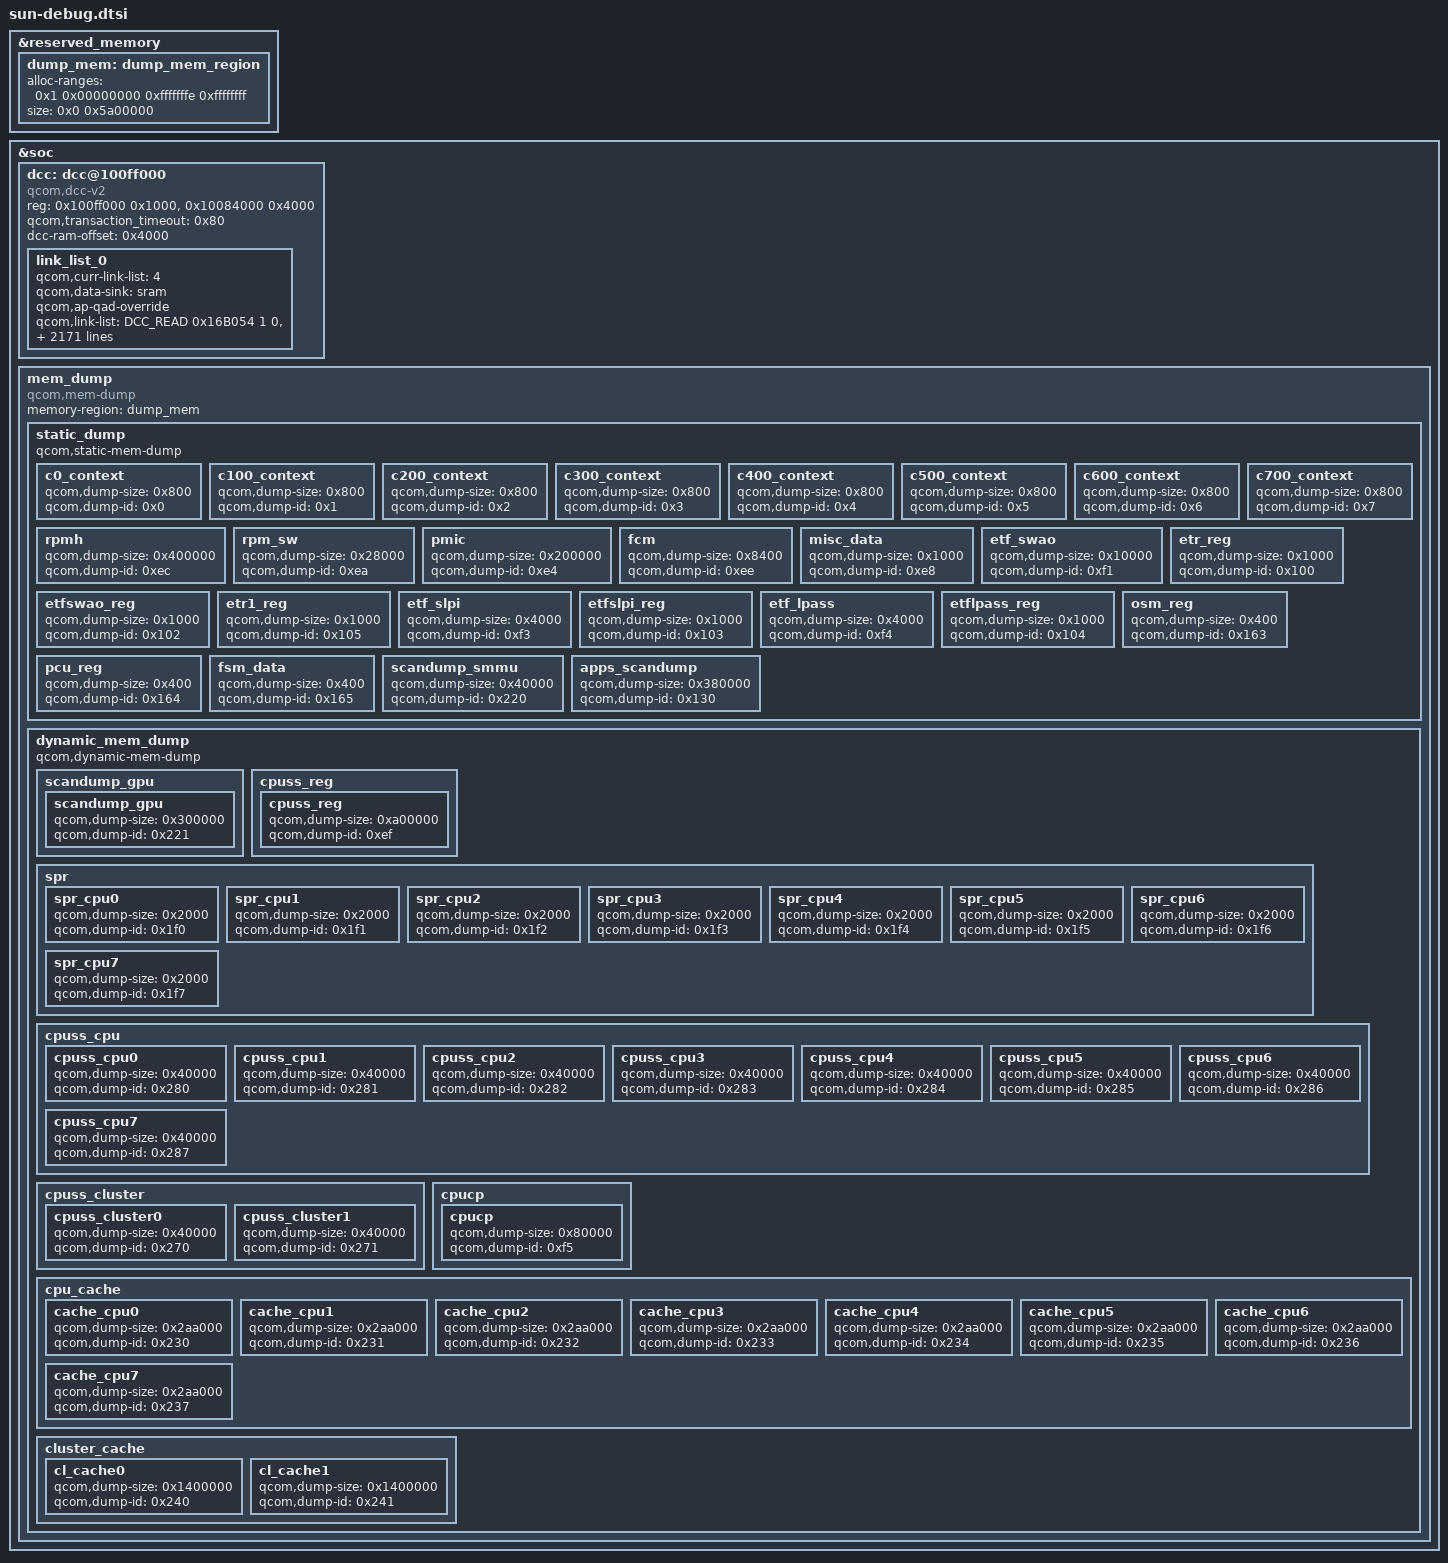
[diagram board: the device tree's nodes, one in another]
// SPDX-License-Identifier: BSD-3-Clause
/*
 * Copyright (c) 2023-2024 Qualcomm Innovation Center, Inc. All rights reserved.
 */

#include <dt-bindings/soc/qcom,dcc_v2.h>

&reserved_memory {
	#address-cells = <2>;
	#size-cells = <2>;
	ranges;

	dump_mem: dump_mem_region {
		alloc-ranges = <0x1 0x00000000 0xfffffffe 0xffffffff>;
		size = <0x0 0x5a00000>;
	};
};

&soc {
	dcc: dcc@100ff000 {
		compatible = "qcom,dcc-v2";
		reg = <0x100ff000 0x1000>,
		      <0x10084000 0x4000>;
		reg-names = "dcc-base", "dcc-ram-base";

		qcom,transaction_timeout = <0x80>;
		dcc-ram-offset = <0x4000>;

		link_list_0 {
			qcom,curr-link-list = <4>;
			qcom,data-sink = "sram";
			qcom,ap-qad-override;
			qcom,link-list = <DCC_READ 0x16B054  1 0>,
				<DCC_READ 0x16B080  1 0>,
				<DCC_READ 0x16B044  1 0>,
				<DCC_READ 0x16B040  1 0>,
				<DCC_READ 0x16B030  1 0>,
				<DCC_READ 0x16B020  1 0>,
				<DCC_READ 0x16B01C  1 0>,
				<DCC_READ 0x16B064  1 0>,
				<DCC_READ 0x11007C  1 0>,
				<DCC_READ 0x110068  1 0>,
				<DCC_READ 0x110058  1 0>,
				<DCC_READ 0xF204008 1 0>,
				<DCC_READ 0x1c06000 1 0>,
				<DCC_READ 0x1c06004 1 0>,
				<DCC_READ 0x1c06008 1 0>,
				<DCC_READ 0x1c0600c 1 0>,
				<DCC_READ 0x1c06010 1 0>,
				<DCC_READ 0x1c06014 1 0>,
				<DCC_READ 0x1c06018 1 0>,
				<DCC_READ 0x1c0601c 1 0>,
				<DCC_READ 0x1c06020 1 0>,
				<DCC_READ 0x1c06024 1 0>,
				<DCC_READ 0x1c06028 1 0>,
				<DCC_READ 0x1c0602c 1 0>,
				<DCC_READ 0x1c06030 1 0>,
				<DCC_READ 0x1c06034 1 0>,
				<DCC_READ 0x1c06038 1 0>,
				<DCC_READ 0x1c0603c 1 0>,
				<DCC_READ 0x1c06040 1 0>,
				<DCC_READ 0x1c06044 1 0>,
				<DCC_READ 0x1c06048 1 0>,
				<DCC_READ 0x1c0604c 1 0>,
				<DCC_READ 0x1c06050 1 0>,
				<DCC_READ 0x1c06054 1 0>,
				<DCC_READ 0x1c06058 1 0>,
				<DCC_READ 0x1c0605c 1 0>,
				<DCC_READ 0x1c06060 1 0>,
				<DCC_READ 0x1c06064 1 0>,
				<DCC_READ 0x1c06068 1 0>,
				<DCC_READ 0x1c0606c 1 0>,
				<DCC_READ 0x1c06070 1 0>,
				<DCC_READ 0x1c06074 1 0>,
				<DCC_READ 0x1c06078 1 0>,
				<DCC_READ 0x1c0607c 1 0>,
				<DCC_READ 0x1c06080 1 0>,
				<DCC_READ 0x1c06084 1 0>,
				<DCC_READ 0x1c06088 1 0>,
				<DCC_READ 0x1c0608c 1 0>,
				<DCC_READ 0x1c06090 1 0>,
				<DCC_READ 0x1c06094 1 0>,
				<DCC_READ 0x1c06098 1 0>,
				<DCC_READ 0x1c0609c 1 0>,
				<DCC_READ 0x1c060a0 1 0>,
				<DCC_READ 0x1c060a4 1 0>,
				<DCC_READ 0x1c060a8 1 0>,
				<DCC_READ 0x1c060ac 1 0>,
				<DCC_READ 0x1c060b0 1 0>,
				<DCC_READ 0x1c060b4 1 0>,
				<DCC_READ 0x1c060b8 1 0>,
				<DCC_READ 0x1c060bc 1 0>,
				<DCC_READ 0x1c060c0 1 0>,
				<DCC_READ 0x1c060c4 1 0>,
				<DCC_READ 0x1c060c8 1 0>,
				<DCC_READ 0x1c060cc 1 0>,
				<DCC_READ 0x1c060d0 1 0>,
				<DCC_READ 0x1c060d4 1 0>,
				<DCC_READ 0x1c060d8 1 0>,
				<DCC_READ 0x1c060dc 1 0>,
				<DCC_READ 0x1c060e0 1 0>,
				<DCC_READ 0x1c060e4 1 0>,
				<DCC_READ 0x1c060e8 1 0>,
				<DCC_READ 0x1c060ec 1 0>,
				<DCC_READ 0x1c060f0 1 0>,
				<DCC_READ 0x1c060f4 1 0>,
				<DCC_READ 0x1c060f8 1 0>,
				<DCC_READ 0x1c060fc 1 0>,
				<DCC_READ 0x1c06100 1 0>,
				<DCC_READ 0x1c06104 1 0>,
				<DCC_READ 0x1c06108 1 0>,
				<DCC_READ 0x1c0610c 1 0>,
				<DCC_READ 0x1c06110 1 0>,
				<DCC_READ 0x1c06114 1 0>,
				<DCC_READ 0x1c06118 1 0>,
				<DCC_READ 0x1c0611c 1 0>,
				<DCC_READ 0x1c06120 1 0>,
				<DCC_READ 0x1c06124 1 0>,
				<DCC_READ 0x1c06128 1 0>,
				<DCC_READ 0x1c0612c 1 0>,
				<DCC_READ 0x1c06130 1 0>,
				<DCC_READ 0x1c06134 1 0>,
				<DCC_READ 0x1c06138 1 0>,
				<DCC_READ 0x1c0613c 1 0>,
				<DCC_READ 0x1c06140 1 0>,
				<DCC_READ 0x1c06144 1 0>,
				<DCC_READ 0x1c06148 1 0>,
				<DCC_READ 0x1c0614c 1 0>,
				<DCC_READ 0x1c06150 1 0>,
				<DCC_READ 0x1c06154 1 0>,
				<DCC_READ 0x1c06158 1 0>,
				<DCC_READ 0x1c0615c 1 0>,
				<DCC_READ 0x1c06160 1 0>,
				<DCC_READ 0x1c06164 1 0>,
				<DCC_READ 0x1c06168 1 0>,
				<DCC_READ 0x1c0616c 1 0>,
				<DCC_READ 0x1c06170 1 0>,
				<DCC_READ 0x1c06174 1 0>,
				<DCC_READ 0x1c06178 1 0>,
				<DCC_READ 0x1c0617c 1 0>,
				<DCC_READ 0x1c06180 1 0>,
				<DCC_READ 0x1c06184 1 0>,
				<DCC_READ 0x1c06188 1 0>,
				<DCC_READ 0x1c0618c 1 0>,
				<DCC_READ 0x1c06190 1 0>,
				<DCC_READ 0x1c06194 1 0>,
				<DCC_READ 0x1c06198 1 0>,
				<DCC_READ 0x1c0619c 1 0>,
				<DCC_READ 0x1c061a0 1 0>,
				<DCC_READ 0x1c061a4 1 0>,
				<DCC_READ 0x1c061a8 1 0>,
				<DCC_READ 0x1c061ac 1 0>,
				<DCC_READ 0x1c061b0 1 0>,
				<DCC_READ 0x1c061b4 1 0>,
				<DCC_READ 0x1c061b8 1 0>,
				<DCC_READ 0x1c061bc 1 0>,
				<DCC_READ 0x1c061c0 1 0>,
				<DCC_READ 0x1c061c4 1 0>,
				<DCC_READ 0x1c061c8 1 0>,
				<DCC_READ 0x1c061cc 1 0>,
				<DCC_READ 0x1c061d0 1 0>,
				<DCC_READ 0x1c061d4 1 0>,
				<DCC_READ 0x1c061d8 1 0>,
				<DCC_READ 0x1c061dc 1 0>,
				<DCC_READ 0x1c061e0 1 0>,
				<DCC_READ 0x1c061e4 1 0>,
				<DCC_READ 0x1c061e8 1 0>,
				<DCC_READ 0x1c061ec 1 0>,
				<DCC_READ 0x1c061f0 1 0>,
				<DCC_READ 0x1c061f4 1 0>,
				<DCC_READ 0x1c061f8 1 0>,
				<DCC_READ 0x1c061fc 1 0>,
				<DCC_READ 0x1c06200 1 0>,
				<DCC_READ 0x1c06204 1 0>,
				<DCC_READ 0x1c06208 1 0>,
				<DCC_READ 0x1c0620c 1 0>,
				<DCC_READ 0x1c06210 1 0>,
				<DCC_READ 0x1c06214 1 0>,
				<DCC_READ 0x1c06218 1 0>,
				<DCC_READ 0x1c0621c 1 0>,
				<DCC_READ 0x1c06220 1 0>,
				<DCC_READ 0x1c06224 1 0>,
				<DCC_READ 0x1c06228 1 0>,
				<DCC_READ 0x1c0622c 1 0>,
				<DCC_READ 0x1c06230 1 0>,
				<DCC_READ 0x1c06234 1 0>,
				<DCC_READ 0x1c06238 1 0>,
				<DCC_READ 0x1c0623c 1 0>,
				<DCC_READ 0x1c06240 1 0>,
				<DCC_READ 0x1c06244 1 0>,
				<DCC_READ 0x1c06248 1 0>,
				<DCC_READ 0x1c0624c 1 0>,
				<DCC_READ 0x1c06250 1 0>,
				<DCC_READ 0x1c06254 1 0>,
				<DCC_READ 0x1c06258 1 0>,
				<DCC_READ 0x1c0625c 1 0>,
				<DCC_READ 0x1c06260 1 0>,
				<DCC_READ 0x1c06264 1 0>,
				<DCC_READ 0x1c06268 1 0>,
				<DCC_READ 0x1c0626c 1 0>,
				<DCC_READ 0x1c06270 1 0>,
				<DCC_READ 0x1c06274 1 0>,
				<DCC_READ 0x1c06278 1 0>,
				<DCC_READ 0x1c0627c 1 0>,
				<DCC_READ 0x1c06280 1 0>,
				<DCC_READ 0x1c06284 1 0>,
				<DCC_READ 0x1c06288 1 0>,
				<DCC_READ 0x1c0628c 1 0>,
				<DCC_READ 0x1c06290 1 0>,
				<DCC_READ 0x1c06294 1 0>,
				<DCC_READ 0x1c06298 1 0>,
				<DCC_READ 0x1c0629c 1 0>,
				<DCC_READ 0x1c062a0 1 0>,
				<DCC_READ 0x1c062a4 1 0>,
				<DCC_READ 0x1c062a8 1 0>,
				<DCC_READ 0x1c062ac 1 0>,
				<DCC_READ 0x1c062b0 1 0>,
				<DCC_READ 0x1c062b4 1 0>,
				<DCC_READ 0x1c062b8 1 0>,
				<DCC_READ 0x1c062bc 1 0>,
				<DCC_READ 0x1c062c0 1 0>,
				<DCC_READ 0x1c062c4 1 0>,
				<DCC_READ 0x1c062c8 1 0>,
				<DCC_READ 0x1c062cc 1 0>,
				<DCC_READ 0x1c062d0 1 0>,
				<DCC_READ 0x1c062d4 1 0>,
				<DCC_READ 0x1c062d8 1 0>,
				<DCC_READ 0x1c062dc 1 0>,
				<DCC_READ 0x1c062e0 1 0>,
				<DCC_READ 0x1c062e4 1 0>,
				<DCC_READ 0x1c062e8 1 0>,
				<DCC_READ 0x1c062ec 1 0>,
				<DCC_READ 0x1c062f0 1 0>,
				<DCC_READ 0x1c062f4 1 0>,
				<DCC_READ 0x1c062f8 1 0>,
				<DCC_READ 0x1c062fc 1 0>,
				<DCC_READ 0x1c06300 1 0>,
				<DCC_READ 0x1c06304 1 0>,
				<DCC_READ 0x1c06308 1 0>,
				<DCC_READ 0x1c0630c 1 0>,
				<DCC_READ 0x1c06310 1 0>,
				<DCC_READ 0x1c06314 1 0>,
				<DCC_READ 0x1c06318 1 0>,
				<DCC_READ 0x1c0631c 1 0>,
				<DCC_READ 0x1c06320 1 0>,
				<DCC_READ 0x1c06324 1 0>,
				<DCC_READ 0x1c06328 1 0>,
				<DCC_READ 0x1c0632c 1 0>,
				<DCC_READ 0x1c06330 1 0>,
				<DCC_READ 0x1c06334 1 0>,
				<DCC_READ 0x1c06338 1 0>,
				<DCC_READ 0x1c0633c 1 0>,
				<DCC_READ 0x1c06340 1 0>,
				<DCC_READ 0x1c06344 1 0>,
				<DCC_READ 0x1c06348 1 0>,
				<DCC_READ 0x1c0634c 1 0>,
				<DCC_READ 0x1c06350 1 0>,
				<DCC_READ 0x1c06354 1 0>,
				<DCC_READ 0x1c06358 1 0>,
				<DCC_READ 0x1c0635c 1 0>,
				<DCC_READ 0x1c06360 1 0>,
				<DCC_READ 0x1c06364 1 0>,
				<DCC_READ 0x1c06368 1 0>,
				<DCC_READ 0x1c0636c 1 0>,
				<DCC_READ 0x1c06370 1 0>,
				<DCC_READ 0x1c06374 1 0>,
				<DCC_READ 0x1c06378 1 0>,
				<DCC_READ 0x1c0637c 1 0>,
				<DCC_READ 0x1c06380 1 0>,
				<DCC_READ 0x1c06384 1 0>,
				<DCC_READ 0x1c06388 1 0>,
				<DCC_READ 0x1c0638c 1 0>,
				<DCC_READ 0x1c06390 1 0>,
				<DCC_READ 0x1c06394 1 0>,
				<DCC_READ 0x1c06398 1 0>,
				<DCC_READ 0x1c0639c 1 0>,
				<DCC_READ 0x1c063a0 1 0>,
				<DCC_READ 0x1c063a4 1 0>,
				<DCC_READ 0x1c063a8 1 0>,
				<DCC_READ 0x1c063ac 1 0>,
				<DCC_READ 0x1c063b0 1 0>,
				<DCC_READ 0x1c063b4 1 0>,
				<DCC_READ 0x1c063b8 1 0>,
				<DCC_READ 0x1c063bc 1 0>,
				<DCC_READ 0x1c063c0 1 0>,
				<DCC_READ 0x1c063c4 1 0>,
				<DCC_READ 0x1c063c8 1 0>,
				<DCC_READ 0x1c063cc 1 0>,
				<DCC_READ 0x1c063d0 1 0>,
				<DCC_READ 0x1c063d4 1 0>,
				<DCC_READ 0x1c063d8 1 0>,
				<DCC_READ 0x1c063dc 1 0>,
				<DCC_READ 0x1c063e0 1 0>,
				<DCC_READ 0x1c063e4 1 0>,
				<DCC_READ 0x1c063e8 1 0>,
				<DCC_READ 0x1c063ec 1 0>,
				<DCC_READ 0x1c063f0 1 0>,
				<DCC_READ 0x1c063f4 1 0>,
				<DCC_READ 0x1c063f8 1 0>,
				<DCC_READ 0x1c063fc 1 0>,
				<DCC_READ 0x1c06400 1 0>,
				<DCC_READ 0x1c06404 1 0>,
				<DCC_READ 0x1c06408 1 0>,
				<DCC_READ 0x1c0640c 1 0>,
				<DCC_READ 0x1c06410 1 0>,
				<DCC_READ 0x1c06414 1 0>,
				<DCC_READ 0x1c06418 1 0>,
				<DCC_READ 0x1c0641c 1 0>,
				<DCC_READ 0x1c06420 1 0>,
				<DCC_READ 0x1c06424 1 0>,
				<DCC_READ 0x1c06428 1 0>,
				<DCC_READ 0x1c0642c 1 0>,
				<DCC_READ 0x1c06430 1 0>,
				<DCC_READ 0x1c06434 1 0>,
				<DCC_READ 0x1c06438 1 0>,
				<DCC_READ 0x1c0643c 1 0>,
				<DCC_READ 0x1c06440 1 0>,
				<DCC_READ 0x1c06444 1 0>,
				<DCC_READ 0x1c06448 1 0>,
				<DCC_READ 0x1c0644c 1 0>,
				<DCC_READ 0x1c06450 1 0>,
				<DCC_READ 0x1c06454 1 0>,
				<DCC_READ 0x1c06458 1 0>,
				<DCC_READ 0x1c0645c 1 0>,
				<DCC_READ 0x1c06460 1 0>,
				<DCC_READ 0x1c06464 1 0>,
				<DCC_READ 0x1c06468 1 0>,
				<DCC_READ 0x1c0646c 1 0>,
				<DCC_READ 0x1c06470 1 0>,
				<DCC_READ 0x1c06474 1 0>,
				<DCC_READ 0x1c06478 1 0>,
				<DCC_READ 0x1c0647c 1 0>,
				<DCC_READ 0x1c06480 1 0>,
				<DCC_READ 0x1c06484 1 0>,
				<DCC_READ 0x1c06488 1 0>,
				<DCC_READ 0x1c0648c 1 0>,
				<DCC_READ 0x1c06490 1 0>,
				<DCC_READ 0x1c06494 1 0>,
				<DCC_READ 0x1c06498 1 0>,
				<DCC_READ 0x1c0649c 1 0>,
				<DCC_READ 0x1c064a0 1 0>,
				<DCC_READ 0x1c064a4 1 0>,
				<DCC_READ 0x1c064a8 1 0>,
				<DCC_READ 0x1c064ac 1 0>,
				<DCC_READ 0x1c064b0 1 0>,
				<DCC_READ 0x1c064b4 1 0>,
				<DCC_READ 0x1c064b8 1 0>,
				<DCC_READ 0x1c064bc 1 0>,
				<DCC_READ 0x1c064c0 1 0>,
				<DCC_READ 0x1c064c4 1 0>,
				<DCC_READ 0x1c064c8 1 0>,
				<DCC_READ 0x1c064cc 1 0>,
				<DCC_READ 0x1c064d0 1 0>,
				<DCC_READ 0x1c064d4 1 0>,
				<DCC_READ 0x1c064d8 1 0>,
				<DCC_READ 0x1c064dc 1 0>,
				<DCC_READ 0x1c064e0 1 0>,
				<DCC_READ 0x1c064e4 1 0>,
				<DCC_READ 0x1c064e8 1 0>,
				<DCC_READ 0x1c064ec 1 0>,
				<DCC_READ 0x1c064f0 1 0>,
				<DCC_READ 0x1c064f4 1 0>,
				<DCC_READ 0x1c064f8 1 0>,
				<DCC_READ 0x1c064fc 1 0>,
				<DCC_READ 0x1c06500 1 0>,
				<DCC_READ 0x1c06504 1 0>,
				<DCC_READ 0x1c06508 1 0>,
				<DCC_READ 0x1c0650c 1 0>,
				<DCC_READ 0x1c06510 1 0>,
				<DCC_READ 0x1c06514 1 0>,
				<DCC_READ 0x1c06518 1 0>,
				<DCC_READ 0x1c0651c 1 0>,
				<DCC_READ 0x1c06520 1 0>,
				<DCC_READ 0x1c06524 1 0>,
				<DCC_READ 0x1c06528 1 0>,
				<DCC_READ 0x1c0652c 1 0>,
				<DCC_READ 0x1c06530 1 0>,
				<DCC_READ 0x1c06534 1 0>,
				<DCC_READ 0x1c06538 1 0>,
				<DCC_READ 0x1c0653c 1 0>,
				<DCC_READ 0x1c06540 1 0>,
				<DCC_READ 0x1c06544 1 0>,
				<DCC_READ 0x1c06548 1 0>,
				<DCC_READ 0x1c0654c 1 0>,
				<DCC_READ 0x1c06550 1 0>,
				<DCC_READ 0x1c06554 1 0>,
				<DCC_READ 0x1c06558 1 0>,
				<DCC_READ 0x1c0655c 1 0>,
				<DCC_READ 0x1c06560 1 0>,
				<DCC_READ 0x1c06564 1 0>,
				<DCC_READ 0x1c06568 1 0>,
				<DCC_READ 0x1c0656c 1 0>,
				<DCC_READ 0x1c06570 1 0>,
				<DCC_READ 0x1c06574 1 0>,
				<DCC_READ 0x1c06578 1 0>,
				<DCC_READ 0x1c0657c 1 0>,
				<DCC_READ 0x1c06580 1 0>,
				<DCC_READ 0x1c06584 1 0>,
				<DCC_READ 0x1c06588 1 0>,
				<DCC_READ 0x1c0658c 1 0>,
				<DCC_READ 0x1c06590 1 0>,
				<DCC_READ 0x1c06594 1 0>,
				<DCC_READ 0x1c06598 1 0>,
				<DCC_READ 0x1c0659c 1 0>,
				<DCC_READ 0x1c065a0 1 0>,
				<DCC_READ 0x1c065a4 1 0>,
				<DCC_READ 0x1c065a8 1 0>,
				<DCC_READ 0x1c065ac 1 0>,
				<DCC_READ 0x1c065b0 1 0>,
				<DCC_READ 0x1c065b4 1 0>,
				<DCC_READ 0x1c065b8 1 0>,
				<DCC_READ 0x1c065bc 1 0>,
				<DCC_READ 0x1c065c0 1 0>,
				<DCC_READ 0x1c065c4 1 0>,
				<DCC_READ 0x1c065c8 1 0>,
				<DCC_READ 0x1c065cc 1 0>,
				<DCC_READ 0x1c065d0 1 0>,
				<DCC_READ 0x1c065d4 1 0>,
				<DCC_READ 0x1c065d8 1 0>,
				<DCC_READ 0x1c065dc 1 0>,
				<DCC_READ 0x1c065e0 1 0>,
				<DCC_READ 0x1c065e4 1 0>,
				<DCC_READ 0x1c065e8 1 0>,
				<DCC_READ 0x1c065ec 1 0>,
				<DCC_READ 0x1c065f0 1 0>,
				<DCC_READ 0x1c065f4 1 0>,
				<DCC_READ 0x1c065f8 1 0>,
				<DCC_READ 0x1c065fc 1 0>,
				<DCC_READ 0x1c06600 1 0>,
				<DCC_READ 0x1c06604 1 0>,
				<DCC_READ 0x1c06608 1 0>,
				<DCC_READ 0x1c0660c 1 0>,
				<DCC_READ 0x1c06610 1 0>,
				<DCC_READ 0x1c06614 1 0>,
				<DCC_READ 0x1c06618 1 0>,
				<DCC_READ 0x1c0661c 1 0>,
				<DCC_READ 0x1c06620 1 0>,
				<DCC_READ 0x1c06624 1 0>,
				<DCC_READ 0x1c06628 1 0>,
				<DCC_READ 0x1c0662c 1 0>,
				<DCC_READ 0x1c06630 1 0>,
				<DCC_READ 0x1c06634 1 0>,
				<DCC_READ 0x1c06638 1 0>,
				<DCC_READ 0x1c0663c 1 0>,
				<DCC_READ 0x1c06640 1 0>,
				<DCC_READ 0x1c06644 1 0>,
				<DCC_READ 0x1c06648 1 0>,
				<DCC_READ 0x1c0664c 1 0>,
				<DCC_READ 0x1c06650 1 0>,
				<DCC_READ 0x1c06654 1 0>,
				<DCC_READ 0x1c06658 1 0>,
				<DCC_READ 0x1c0665c 1 0>,
				<DCC_READ 0x1c06660 1 0>,
				<DCC_READ 0x1c06664 1 0>,
				<DCC_READ 0x1c06668 1 0>,
				<DCC_READ 0x1c0666c 1 0>,
				<DCC_READ 0x1c06670 1 0>,
				<DCC_READ 0x1c06674 1 0>,
				<DCC_READ 0x1c06678 1 0>,
				<DCC_READ 0x1c0667c 1 0>,
				<DCC_READ 0x1c06680 1 0>,
				<DCC_READ 0x1c06684 1 0>,
				<DCC_READ 0x1c06688 1 0>,
				<DCC_READ 0x1c0668c 1 0>,
				<DCC_READ 0x1c06690 1 0>,
				<DCC_READ 0x1c06694 1 0>,
				<DCC_READ 0x1c06698 1 0>,
				<DCC_READ 0x1c0669c 1 0>,
				<DCC_READ 0x1c066a0 1 0>,
				<DCC_READ 0x1c066a4 1 0>,
				<DCC_READ 0x1c066a8 1 0>,
				<DCC_READ 0x1c066ac 1 0>,
				<DCC_READ 0x1c066b0 1 0>,
				<DCC_READ 0x1c066b4 1 0>,
				<DCC_READ 0x1c066b8 1 0>,
				<DCC_READ 0x1c066bc 1 0>,
				<DCC_READ 0x1c066c0 1 0>,
				<DCC_READ 0x1c066c4 1 0>,
				<DCC_READ 0x1c066c8 1 0>,
				<DCC_READ 0x1c066cc 1 0>,
				<DCC_READ 0x1c066d0 1 0>,
				<DCC_READ 0x1c066d4 1 0>,
				<DCC_READ 0x1c066d8 1 0>,
				<DCC_READ 0x1c066dc 1 0>,
				<DCC_READ 0x1c066e0 1 0>,
				<DCC_READ 0x1c066e4 1 0>,
				<DCC_READ 0x1c066e8 1 0>,
				<DCC_READ 0x1c066ec 1 0>,
				<DCC_READ 0x1c066f0 1 0>,
				<DCC_READ 0x1c066f4 1 0>,
				<DCC_READ 0x1c066f8 1 0>,
				<DCC_READ 0x1c066fc 1 0>,
				<DCC_READ 0x1c06700 1 0>,
				<DCC_READ 0x1c06704 1 0>,
				<DCC_READ 0x1c06708 1 0>,
				<DCC_READ 0x1c0670c 1 0>,
				<DCC_READ 0x1c06710 1 0>,
				<DCC_READ 0x1c06714 1 0>,
				<DCC_READ 0x1c06718 1 0>,
				<DCC_READ 0x1c0671c 1 0>,
				<DCC_READ 0x1c06720 1 0>,
				<DCC_READ 0x1c06724 1 0>,
				<DCC_READ 0x1c06728 1 0>,
				<DCC_READ 0x1c0672c 1 0>,
				<DCC_READ 0x1c06730 1 0>,
				<DCC_READ 0x1c06734 1 0>,
				<DCC_READ 0x1c06738 1 0>,
				<DCC_READ 0x1c0673c 1 0>,
				<DCC_READ 0x1c06740 1 0>,
				<DCC_READ 0x1c06744 1 0>,
				<DCC_READ 0x1c06748 1 0>,
				<DCC_READ 0x1c0674c 1 0>,
				<DCC_READ 0x1c06750 1 0>,
				<DCC_READ 0x1c06754 1 0>,
				<DCC_READ 0x1c06758 1 0>,
				<DCC_READ 0x1c0675c 1 0>,
				<DCC_READ 0x1c06760 1 0>,
				<DCC_READ 0x1c06764 1 0>,
				<DCC_READ 0x1c06768 1 0>,
				<DCC_READ 0x1c0676c 1 0>,
				<DCC_READ 0x1c06770 1 0>,
				<DCC_READ 0x1c06774 1 0>,
				<DCC_READ 0x1c06778 1 0>,
				<DCC_READ 0x1c0677c 1 0>,
				<DCC_READ 0x1c06780 1 0>,
				<DCC_READ 0x1c06784 1 0>,
				<DCC_READ 0x1c06788 1 0>,
				<DCC_READ 0x1c0678c 1 0>,
				<DCC_READ 0x1c06790 1 0>,
				<DCC_READ 0x1c06794 1 0>,
				<DCC_READ 0x1c06798 1 0>,
				<DCC_READ 0x1c0679c 1 0>,
				<DCC_READ 0x1c067a0 1 0>,
				<DCC_READ 0x1c067a4 1 0>,
				<DCC_READ 0x1c067a8 1 0>,
				<DCC_READ 0x1c067ac 1 0>,
				<DCC_READ 0x1c067b0 1 0>,
				<DCC_READ 0x1c067b4 1 0>,
				<DCC_READ 0x1c067b8 1 0>,
				<DCC_READ 0x1c067bc 1 0>,
				<DCC_READ 0x1c067c0 1 0>,
				<DCC_READ 0x1c067c4 1 0>,
				<DCC_READ 0x1c067c8 1 0>,
				<DCC_READ 0x1c067cc 1 0>,
				<DCC_READ 0x1c067d0 1 0>,
				<DCC_READ 0x1c067d4 1 0>,
				<DCC_READ 0x1c067d8 1 0>,
				<DCC_READ 0x1c067dc 1 0>,
				<DCC_READ 0x1c067e0 1 0>,
				<DCC_READ 0x1c067e4 1 0>,
				<DCC_READ 0x1c067e8 1 0>,
				<DCC_READ 0x1c067ec 1 0>,
				<DCC_READ 0x1c067f0 1 0>,
				<DCC_READ 0x1c067f4 1 0>,
				<DCC_READ 0x1c067f8 1 0>,
				<DCC_READ 0x1c067fc 1 0>,
				<DCC_READ 0x1c06800 1 0>,
				<DCC_READ 0x1c06804 1 0>,
				<DCC_READ 0x1c06808 1 0>,
				<DCC_READ 0x1c0680c 1 0>,
				<DCC_READ 0x1c06810 1 0>,
				<DCC_READ 0x1c06814 1 0>,
				<DCC_READ 0x1c06818 1 0>,
				<DCC_READ 0x1c0681c 1 0>,
				<DCC_READ 0x1c06820 1 0>,
				<DCC_READ 0x1c06824 1 0>,
				<DCC_READ 0x1c06828 1 0>,
				<DCC_READ 0x1c0682c 1 0>,
				<DCC_READ 0x1c06830 1 0>,
				<DCC_READ 0x1c06834 1 0>,
				<DCC_READ 0x1c06838 1 0>,
				<DCC_READ 0x1c0683c 1 0>,
				<DCC_READ 0x1c06840 1 0>,
				<DCC_READ 0x1c06844 1 0>,
				<DCC_READ 0x1c06848 1 0>,
				<DCC_READ 0x1c0684c 1 0>,
				<DCC_READ 0x1c06850 1 0>,
				<DCC_READ 0x1c06854 1 0>,
				<DCC_READ 0x1c06858 1 0>,
				<DCC_READ 0x1c0685c 1 0>,
				<DCC_READ 0x1c06860 1 0>,
				<DCC_READ 0x1c06864 1 0>,
				<DCC_READ 0x1c06868 1 0>,
				<DCC_READ 0x1c0686c 1 0>,
				<DCC_READ 0x1c06870 1 0>,
				<DCC_READ 0x1c06874 1 0>,
				<DCC_READ 0x1c06878 1 0>,
				<DCC_READ 0x1c0687c 1 0>,
				<DCC_READ 0x1c06880 1 0>,
				<DCC_READ 0x1c06884 1 0>,
				<DCC_READ 0x1c06888 1 0>,
				<DCC_READ 0x1c0688c 1 0>,
				<DCC_READ 0x1c06890 1 0>,
				<DCC_READ 0x1c06894 1 0>,
				<DCC_READ 0x1c06898 1 0>,
				<DCC_READ 0x1c0689c 1 0>,
				<DCC_READ 0x1c068a0 1 0>,
				<DCC_READ 0x1c068a4 1 0>,
				<DCC_READ 0x1c068a8 1 0>,
				<DCC_READ 0x1c068ac 1 0>,
				<DCC_READ 0x1c068b0 1 0>,
				<DCC_READ 0x1c068b4 1 0>,
				<DCC_READ 0x1c068b8 1 0>,
				<DCC_READ 0x1c068bc 1 0>,
				<DCC_READ 0x1c068c0 1 0>,
				<DCC_READ 0x1c068c4 1 0>,
				<DCC_READ 0x1c068c8 1 0>,
				<DCC_READ 0x1c068cc 1 0>,
				<DCC_READ 0x1c068d0 1 0>,
				<DCC_READ 0x1c068d4 1 0>,
				<DCC_READ 0x1c068d8 1 0>,
				<DCC_READ 0x1c068dc 1 0>,
				<DCC_READ 0x1c068e0 1 0>,
				<DCC_READ 0x1c068e4 1 0>,
				<DCC_READ 0x1c068e8 1 0>,
				<DCC_READ 0x1c068ec 1 0>,
				<DCC_READ 0x1c068f0 1 0>,
				<DCC_READ 0x1c068f4 1 0>,
				<DCC_READ 0x1c068f8 1 0>,
				<DCC_READ 0x1c068fc 1 0>,
				<DCC_READ 0x1c06900 1 0>,
				<DCC_READ 0x1c06904 1 0>,
				<DCC_READ 0x1c06908 1 0>,
				<DCC_READ 0x1c0690c 1 0>,
				<DCC_READ 0x1c06910 1 0>,
				<DCC_READ 0x1c06914 1 0>,
				<DCC_READ 0x1c06918 1 0>,
				<DCC_READ 0x1c0691c 1 0>,
				<DCC_READ 0x1c06920 1 0>,
				<DCC_READ 0x1c06924 1 0>,
				<DCC_READ 0x1c06928 1 0>,
				<DCC_READ 0x1c0692c 1 0>,
				<DCC_READ 0x1c06930 1 0>,
				<DCC_READ 0x1c06934 1 0>,
				<DCC_READ 0x1c06938 1 0>,
				<DCC_READ 0x1c0693c 1 0>,
				<DCC_READ 0x1c06940 1 0>,
				<DCC_READ 0x1c06944 1 0>,
				<DCC_READ 0x1c06948 1 0>,
				<DCC_READ 0x1c0694c 1 0>,
				<DCC_READ 0x1c06950 1 0>,
				<DCC_READ 0x1c06954 1 0>,
				<DCC_READ 0x1c06958 1 0>,
				<DCC_READ 0x1c0695c 1 0>,
				<DCC_READ 0x1c06960 1 0>,
				<DCC_READ 0x1c06964 1 0>,
				<DCC_READ 0x1c06968 1 0>,
				<DCC_READ 0x1c0696c 1 0>,
				<DCC_READ 0x1c06970 1 0>,
				<DCC_READ 0x1c06974 1 0>,
				<DCC_READ 0x1c06978 1 0>,
				<DCC_READ 0x1c0697c 1 0>,
				<DCC_READ 0x1c06980 1 0>,
				<DCC_READ 0x1c06984 1 0>,
				<DCC_READ 0x1c06988 1 0>,
				<DCC_READ 0x1c0698c 1 0>,
				<DCC_READ 0x1c06990 1 0>,
				<DCC_READ 0x1c06994 1 0>,
				<DCC_READ 0x1c06998 1 0>,
				<DCC_READ 0x1c0699c 1 0>,
				<DCC_READ 0x1c069a0 1 0>,
				<DCC_READ 0x1c069a4 1 0>,
				<DCC_READ 0x1c069a8 1 0>,
				<DCC_READ 0x1c069ac 1 0>,
				<DCC_READ 0x1c069b0 1 0>,
				<DCC_READ 0x1c069b4 1 0>,
				<DCC_READ 0x1c069b8 1 0>,
				<DCC_READ 0x1c069bc 1 0>,
				<DCC_READ 0x1c069c0 1 0>,
				<DCC_READ 0x1c069c4 1 0>,
				<DCC_READ 0x1c069c8 1 0>,
				<DCC_READ 0x1c069cc 1 0>,
				<DCC_READ 0x1c069d0 1 0>,
				<DCC_READ 0x1c069d4 1 0>,
				<DCC_READ 0x1c069d8 1 0>,
				<DCC_READ 0x1c069dc 1 0>,
				<DCC_READ 0x1c069e0 1 0>,
				<DCC_READ 0x1c069e4 1 0>,
				<DCC_READ 0x1c069e8 1 0>,
				<DCC_READ 0x1c069ec 1 0>,
				<DCC_READ 0x1c069f0 1 0>,
				<DCC_READ 0x1c069f4 1 0>,
				<DCC_READ 0x1c069f8 1 0>,
				<DCC_READ 0x1c069fc 1 0>,
				<DCC_READ 0x1c06a00 1 0>,
				<DCC_READ 0x1c06a04 1 0>,
				<DCC_READ 0x1c06a08 1 0>,
				<DCC_READ 0x1c06a0c 1 0>,
				<DCC_READ 0x1c06a10 1 0>,
				<DCC_READ 0x1c06a14 1 0>,
				<DCC_READ 0x1c06a18 1 0>,
				<DCC_READ 0x1c06a1c 1 0>,
				<DCC_READ 0x1c06a20 1 0>,
				<DCC_READ 0x1c06a24 1 0>,
				<DCC_READ 0x1c06a28 1 0>,
				<DCC_READ 0x1c06a2c 1 0>,
				<DCC_READ 0x1c06a30 1 0>,
				<DCC_READ 0x1c06a34 1 0>,
				<DCC_READ 0x1c06a38 1 0>,
				<DCC_READ 0x1c06a3c 1 0>,
				<DCC_READ 0x1c06a40 1 0>,
				<DCC_READ 0x1c06a44 1 0>,
				<DCC_READ 0x1c06a48 1 0>,
				<DCC_READ 0x1c06a4c 1 0>,
				<DCC_READ 0x1c06a50 1 0>,
				<DCC_READ 0x1c06a54 1 0>,
				<DCC_READ 0x1c06a58 1 0>,
				<DCC_READ 0x1c06a5c 1 0>,
				<DCC_READ 0x1c06a60 1 0>,
				<DCC_READ 0x1c06a64 1 0>,
				<DCC_READ 0x1c06a68 1 0>,
				<DCC_READ 0x1c06a6c 1 0>,
				<DCC_READ 0x1c06a70 1 0>,
				<DCC_READ 0x1c06a74 1 0>,
				<DCC_READ 0x1c06a78 1 0>,
				<DCC_READ 0x1c06a7c 1 0>,
				<DCC_READ 0x1c06a80 1 0>,
				<DCC_READ 0x1c06a84 1 0>,
				<DCC_READ 0x1c06a88 1 0>,
				<DCC_READ 0x1c06a8c 1 0>,
				<DCC_READ 0x1c06a90 1 0>,
				<DCC_READ 0x1c06a94 1 0>,
				<DCC_READ 0x1c06a98 1 0>,
				<DCC_READ 0x1c06a9c 1 0>,
				<DCC_READ 0x1c06aa0 1 0>,
				<DCC_READ 0x1c06aa4 1 0>,
				<DCC_READ 0x1c06aa8 1 0>,
				<DCC_READ 0x1c06aac 1 0>,
				<DCC_READ 0x1c06ab0 1 0>,
				<DCC_READ 0x1c06ab4 1 0>,
				<DCC_READ 0x1c06ab8 1 0>,
				<DCC_READ 0x1c06abc 1 0>,
				<DCC_READ 0x1c06ac0 1 0>,
				<DCC_READ 0x1c06ac4 1 0>,
				<DCC_READ 0x1c06ac8 1 0>,
				<DCC_READ 0x1c06acc 1 0>,
				<DCC_READ 0x1c06ad0 1 0>,
				<DCC_READ 0x1c06ad4 1 0>,
				<DCC_READ 0x1c06ad8 1 0>,
				<DCC_READ 0x1c06adc 1 0>,
				<DCC_READ 0x1c06ae0 1 0>,
				<DCC_READ 0x1c06ae4 1 0>,
				<DCC_READ 0x1c06ae8 1 0>,
				<DCC_READ 0x1c06aec 1 0>,
				<DCC_READ 0x1c06af0 1 0>,
				<DCC_READ 0x1c06af4 1 0>,
				<DCC_READ 0x1c06af8 1 0>,
				<DCC_READ 0x1c06afc 1 0>,
				<DCC_READ 0x1c06b00 1 0>,
				<DCC_READ 0x1c06b04 1 0>,
				<DCC_READ 0x1c06b08 1 0>,
				<DCC_READ 0x1c06b0c 1 0>,
				<DCC_READ 0x1c06b10 1 0>,
				<DCC_READ 0x1c06b14 1 0>,
				<DCC_READ 0x1c06b18 1 0>,
				<DCC_READ 0x1c06b1c 1 0>,
				<DCC_READ 0x1c06b20 1 0>,
				<DCC_READ 0x1c06b24 1 0>,
				<DCC_READ 0x1c06b28 1 0>,
				<DCC_READ 0x1c06b2c 1 0>,
				<DCC_READ 0x1c06b30 1 0>,
				<DCC_READ 0x1c06b34 1 0>,
				<DCC_READ 0x1c06b38 1 0>,
				<DCC_READ 0x1c06b3c 1 0>,
				<DCC_READ 0x1c06b40 1 0>,
				<DCC_READ 0x1c06b44 1 0>,
				<DCC_READ 0x1c06b48 1 0>,
				<DCC_READ 0x1c06b4c 1 0>,
				<DCC_READ 0x1c06b50 1 0>,
				<DCC_READ 0x1c06b54 1 0>,
				<DCC_READ 0x1c06b58 1 0>,
				<DCC_READ 0x1c06b5c 1 0>,
				<DCC_READ 0x1c06b60 1 0>,
				<DCC_READ 0x1c06b64 1 0>,
				<DCC_READ 0x1c06b68 1 0>,
				<DCC_READ 0x1c06b6c 1 0>,
				<DCC_READ 0x1c06b70 1 0>,
				<DCC_READ 0x1c06b74 1 0>,
				<DCC_READ 0x1c06b78 1 0>,
				<DCC_READ 0x1c06b7c 1 0>,
				<DCC_READ 0x1c06b80 1 0>,
				<DCC_READ 0x1c06b84 1 0>,
				<DCC_READ 0x1c06b88 1 0>,
				<DCC_READ 0x1c06b8c 1 0>,
				<DCC_READ 0x1c06b90 1 0>,
				<DCC_READ 0x1c06b94 1 0>,
				<DCC_READ 0x1c06b98 1 0>,
				<DCC_READ 0x1c06b9c 1 0>,
				<DCC_READ 0x1c06ba0 1 0>,
				<DCC_READ 0x1c06ba4 1 0>,
				<DCC_READ 0x1c06ba8 1 0>,
				<DCC_READ 0x1c06bac 1 0>,
				<DCC_READ 0x1c06bb0 1 0>,
				<DCC_READ 0x1c06bb4 1 0>,
				<DCC_READ 0x1c06bb8 1 0>,
				<DCC_READ 0x1c06bbc 1 0>,
				<DCC_READ 0x1c06bc0 1 0>,
				<DCC_READ 0x1c06bc4 1 0>,
				<DCC_READ 0x1c06bc8 1 0>,
				<DCC_READ 0x1c06bcc 1 0>,
				<DCC_READ 0x1c06bd0 1 0>,
				<DCC_READ 0x1c06bd4 1 0>,
				<DCC_READ 0x1c06bd8 1 0>,
				<DCC_READ 0x1c06bdc 1 0>,
				<DCC_READ 0x1c06be0 1 0>,
				<DCC_READ 0x1c06be4 1 0>,
				<DCC_READ 0x1c06be8 1 0>,
				<DCC_READ 0x1c06bec 1 0>,
				<DCC_READ 0x1c06bf0 1 0>,
				<DCC_READ 0x1c06bf4 1 0>,
				<DCC_READ 0x1c06bf8 1 0>,
				<DCC_READ 0x1c06bfc 1 0>,
				<DCC_READ 0x1c06c00 1 0>,
				<DCC_READ 0x1c06c04 1 0>,
				<DCC_READ 0x1c06c08 1 0>,
				<DCC_READ 0x1c06c0c 1 0>,
				<DCC_READ 0x1c06c10 1 0>,
				<DCC_READ 0x1c06c14 1 0>,
				<DCC_READ 0x1c06c18 1 0>,
				<DCC_READ 0x1c06c1c 1 0>,
				<DCC_READ 0x1c06c20 1 0>,
				<DCC_READ 0x1c06c24 1 0>,
				<DCC_READ 0x1c06c28 1 0>,
				<DCC_READ 0x1c06c2c 1 0>,
				<DCC_READ 0x1c06c30 1 0>,
				<DCC_READ 0x1c06c34 1 0>,
				<DCC_READ 0x1c06c38 1 0>,
				<DCC_READ 0x1c06c3c 1 0>,
				<DCC_READ 0x1c06c40 1 0>,
				<DCC_READ 0x1c06c44 1 0>,
				<DCC_READ 0x1c06c48 1 0>,
				<DCC_READ 0x1c06c4c 1 0>,
				<DCC_READ 0x1c06c50 1 0>,
				<DCC_READ 0x1c06c54 1 0>,
				<DCC_READ 0x1c06c58 1 0>,
				<DCC_READ 0x1c06c5c 1 0>,
				<DCC_READ 0x1c06c60 1 0>,
				<DCC_READ 0x1c06c64 1 0>,
				<DCC_READ 0x1c06c68 1 0>,
				<DCC_READ 0x1c06c6c 1 0>,
				<DCC_READ 0x1c06c70 1 0>,
				<DCC_READ 0x1c06c74 1 0>,
				<DCC_READ 0x1c06c78 1 0>,
				<DCC_READ 0x1c06c7c 1 0>,
				<DCC_READ 0x1c06c80 1 0>,
				<DCC_READ 0x1c06c84 1 0>,
				<DCC_READ 0x1c06c88 1 0>,
				<DCC_READ 0x1c06c8c 1 0>,
				<DCC_READ 0x1c06c90 1 0>,
				<DCC_READ 0x1c06c94 1 0>,
				<DCC_READ 0x1c06c98 1 0>,
				<DCC_READ 0x1c06c9c 1 0>,
				<DCC_READ 0x1c06ca0 1 0>,
				<DCC_READ 0x1c06ca4 1 0>,
				<DCC_READ 0x1c06ca8 1 0>,
				<DCC_READ 0x1c06cac 1 0>,
				<DCC_READ 0x1c06cb0 1 0>,
				<DCC_READ 0x1c06cb4 1 0>,
				<DCC_READ 0x1c06cb8 1 0>,
				<DCC_READ 0x1c06cbc 1 0>,
				<DCC_READ 0x1c06cc0 1 0>,
				<DCC_READ 0x1c06cc4 1 0>,
				<DCC_READ 0x1c06cc8 1 0>,
				<DCC_READ 0x1c06ccc 1 0>,
				<DCC_READ 0x1c06cd0 1 0>,
				<DCC_READ 0x1c06cd4 1 0>,
				<DCC_READ 0x1c06cd8 1 0>,
				<DCC_READ 0x1c06cdc 1 0>,
				<DCC_READ 0x1c06ce0 1 0>,
				<DCC_READ 0x1c06ce4 1 0>,
				<DCC_READ 0x1c06ce8 1 0>,
				<DCC_READ 0x1c06cec 1 0>,
				<DCC_READ 0x1c06cf0 1 0>,
				<DCC_READ 0x1c06cf4 1 0>,
				<DCC_READ 0x1c06cf8 1 0>,
				<DCC_READ 0x1c06cfc 1 0>,
				<DCC_READ 0x1c06d00 1 0>,
				<DCC_READ 0x1c06d04 1 0>,
				<DCC_READ 0x1c06d08 1 0>,
				<DCC_READ 0x1c06d0c 1 0>,
				<DCC_READ 0x1c06d10 1 0>,
				<DCC_READ 0x1c06d14 1 0>,
				<DCC_READ 0x1c06d18 1 0>,
				<DCC_READ 0x1c06d1c 1 0>,
				<DCC_READ 0x1c06d20 1 0>,
				<DCC_READ 0x1c06d24 1 0>,
				<DCC_READ 0x1c06d28 1 0>,
				<DCC_READ 0x1c06d2c 1 0>,
				<DCC_READ 0x1c06d30 1 0>,
				<DCC_READ 0x1c06d34 1 0>,
				<DCC_READ 0x1c06d38 1 0>,
				<DCC_READ 0x1c06d3c 1 0>,
				<DCC_READ 0x1c06d40 1 0>,
				<DCC_READ 0x1c06d44 1 0>,
				<DCC_READ 0x1c06d48 1 0>,
				<DCC_READ 0x1c06d4c 1 0>,
				<DCC_READ 0x1c06d50 1 0>,
				<DCC_READ 0x1c06d54 1 0>,
				<DCC_READ 0x1c06d58 1 0>,
				<DCC_READ 0x1c06d5c 1 0>,
				<DCC_READ 0x1c06d60 1 0>,
				<DCC_READ 0x1c06d64 1 0>,
				<DCC_READ 0x1c06d68 1 0>,
				<DCC_READ 0x1c06d6c 1 0>,
				<DCC_READ 0x1c06d70 1 0>,
				<DCC_READ 0x1c06d74 1 0>,
				<DCC_READ 0x1c06d78 1 0>,
				<DCC_READ 0x1c06d7c 1 0>,
				<DCC_READ 0x1c06d80 1 0>,
				<DCC_READ 0x1c06d84 1 0>,
				<DCC_READ 0x1c06d88 1 0>,
				<DCC_READ 0x1c06d8c 1 0>,
				<DCC_READ 0x1c06d90 1 0>,
				<DCC_READ 0x1c06d94 1 0>,
				<DCC_READ 0x1c06d98 1 0>,
				<DCC_READ 0x1c06d9c 1 0>,
				<DCC_READ 0x1c06da0 1 0>,
				<DCC_READ 0x1c06da4 1 0>,
				<DCC_READ 0x1c06da8 1 0>,
				<DCC_READ 0x1c06dac 1 0>,
				<DCC_READ 0x1c06db0 1 0>,
				<DCC_READ 0x1c06db4 1 0>,
				<DCC_READ 0x1c06db8 1 0>,
				<DCC_READ 0x1c06dbc 1 0>,
				<DCC_READ 0x1c06dc0 1 0>,
				<DCC_READ 0x1c06dc4 1 0>,
				<DCC_READ 0x1c06dc8 1 0>,
				<DCC_READ 0x1c06dcc 1 0>,
				<DCC_READ 0x1c06dd0 1 0>,
				<DCC_READ 0x1c06dd4 1 0>,
				<DCC_READ 0x1c06dd8 1 0>,
				<DCC_READ 0x1c06ddc 1 0>,
				<DCC_READ 0x1c06de0 1 0>,
				<DCC_READ 0x1c06de4 1 0>,
				<DCC_READ 0x1c06de8 1 0>,
				<DCC_READ 0x1c06dec 1 0>,
				<DCC_READ 0x1c06df0 1 0>,
				<DCC_READ 0x1c06df4 1 0>,
				<DCC_READ 0x1c06df8 1 0>,
				<DCC_READ 0x1c06dfc 1 0>,
				<DCC_READ 0x1c06e00 1 0>,
				<DCC_READ 0x1c06e04 1 0>,
				<DCC_READ 0x1c06e08 1 0>,
				<DCC_READ 0x1c06e0c 1 0>,
				<DCC_READ 0x1c06e10 1 0>,
				<DCC_READ 0x1c06e14 1 0>,
				<DCC_READ 0x1c06e18 1 0>,
				<DCC_READ 0x1c06e1c 1 0>,
				<DCC_READ 0x1c06e20 1 0>,
				<DCC_READ 0x1c06e24 1 0>,
				<DCC_READ 0x1c06e28 1 0>,
				<DCC_READ 0x1c06e2c 1 0>,
				<DCC_READ 0x1c06e30 1 0>,
				<DCC_READ 0x1c06e34 1 0>,
				<DCC_READ 0x1c06e38 1 0>,
				<DCC_READ 0x1c06e3c 1 0>,
				<DCC_READ 0x1c06e40 1 0>,
				<DCC_READ 0x1c06e44 1 0>,
				<DCC_READ 0x1c06e48 1 0>,
				<DCC_READ 0x1c06e4c 1 0>,
				<DCC_READ 0x1c06e50 1 0>,
				<DCC_READ 0x1c06e54 1 0>,
				<DCC_READ 0x1c06e58 1 0>,
				<DCC_READ 0x1c06e5c 1 0>,
				<DCC_READ 0x1c06e60 1 0>,
				<DCC_READ 0x1c06e64 1 0>,
				<DCC_READ 0x1c06e68 1 0>,
				<DCC_READ 0x1c06e6c 1 0>,
				<DCC_READ 0x1c06e70 1 0>,
				<DCC_READ 0x1c06e74 1 0>,
				<DCC_READ 0x1c06e78 1 0>,
				<DCC_READ 0x1c06e7c 1 0>,
				<DCC_READ 0x1c06e80 1 0>,
				<DCC_READ 0x1c06e84 1 0>,
				<DCC_READ 0x1c06e88 1 0>,
				<DCC_READ 0x1c06e8c 1 0>,
				<DCC_READ 0x1c06e90 1 0>,
				<DCC_READ 0x1c06e94 1 0>,
				<DCC_READ 0x1c06e98 1 0>,
				<DCC_READ 0x1c06e9c 1 0>,
				<DCC_READ 0x1c06ea0 1 0>,
				<DCC_READ 0x1c06ea4 1 0>,
				<DCC_READ 0x1c06ea8 1 0>,
				<DCC_READ 0x1c06eac 1 0>,
				<DCC_READ 0x1c06eb0 1 0>,
				<DCC_READ 0x1c06eb4 1 0>,
				<DCC_READ 0x1c06eb8 1 0>,
				<DCC_READ 0x1c06ebc 1 0>,
				<DCC_READ 0x1c06ec0 1 0>,
				<DCC_READ 0x1c06ec4 1 0>,
				<DCC_READ 0x1c06ec8 1 0>,
				<DCC_READ 0x1c06ecc 1 0>,
				<DCC_READ 0x1c06ed0 1 0>,
				<DCC_READ 0x1c06ed4 1 0>,
				<DCC_READ 0x1c06ed8 1 0>,
				<DCC_READ 0x1c06edc 1 0>,
				<DCC_READ 0x1c06ee0 1 0>,
				<DCC_READ 0x1c06ee4 1 0>,
				<DCC_READ 0x1c06ee8 1 0>,
				<DCC_READ 0x1c06eec 1 0>,
				<DCC_READ 0x1c06ef0 1 0>,
				<DCC_READ 0x1c06ef4 1 0>,
				<DCC_READ 0x1c06ef8 1 0>,
				<DCC_READ 0x1c06efc 1 0>,
				<DCC_READ 0x1c06f00 1 0>,
				<DCC_READ 0x1c06f04 1 0>,
				<DCC_READ 0x1c06f08 1 0>,
				<DCC_READ 0x1c06f0c 1 0>,
				<DCC_READ 0x1c06f10 1 0>,
				<DCC_READ 0x1c06f14 1 0>,
				<DCC_READ 0x1c06f18 1 0>,
				<DCC_READ 0x1c06f1c 1 0>,
				<DCC_READ 0x1c06f20 1 0>,
				<DCC_READ 0x1c06f24 1 0>,
				<DCC_READ 0x1c06f28 1 0>,
				<DCC_READ 0x1c06f2c 1 0>,
				<DCC_READ 0x1c06f30 1 0>,
				<DCC_READ 0x1c06f34 1 0>,
				<DCC_READ 0x1c06f38 1 0>,
				<DCC_READ 0x1c06f3c 1 0>,
				<DCC_READ 0x1c06f40 1 0>,
				<DCC_READ 0x1c06f44 1 0>,
				<DCC_READ 0x1c06f48 1 0>,
				<DCC_READ 0x1c06f4c 1 0>,
				<DCC_READ 0x1c06f50 1 0>,
				<DCC_READ 0x1c06f54 1 0>,
				<DCC_READ 0x1c06f58 1 0>,
				<DCC_READ 0x1c06f5c 1 0>,
				<DCC_READ 0x1c06f60 1 0>,
				<DCC_READ 0x1c06f64 1 0>,
				<DCC_READ 0x1c06f68 1 0>,
				<DCC_READ 0x1c06f6c 1 0>,
				<DCC_READ 0x1c06f70 1 0>,
				<DCC_READ 0x1c06f74 1 0>,
				<DCC_READ 0x1c06f78 1 0>,
				<DCC_READ 0x1c06f7c 1 0>,
				<DCC_READ 0x1c06f80 1 0>,
				<DCC_READ 0x1c06f84 1 0>,
				<DCC_READ 0x1c06f88 1 0>,
				<DCC_READ 0x1c06f8c 1 0>,
				<DCC_READ 0x1c06f90 1 0>,
				<DCC_READ 0x1c06f94 1 0>,
				<DCC_READ 0x1c06f98 1 0>,
				<DCC_READ 0x1c06f9c 1 0>,
				<DCC_READ 0x1c06fa0 1 0>,
				<DCC_READ 0x1c06fa4 1 0>,
				<DCC_READ 0x1c06fa8 1 0>,
				<DCC_READ 0x1c06fac 1 0>,
				<DCC_READ 0x1c06fb0 1 0>,
				<DCC_READ 0x1c06fb4 1 0>,
				<DCC_READ 0x1c06fb8 1 0>,
				<DCC_READ 0x1c06fbc 1 0>,
				<DCC_READ 0x1c06fc0 1 0>,
				<DCC_READ 0x1c06fc4 1 0>,
				<DCC_READ 0x1c06fc8 1 0>,
				<DCC_READ 0x1c06fcc 1 0>,
				<DCC_READ 0x1c06fd0 1 0>,
				<DCC_READ 0x1c06fd4 1 0>,
				<DCC_READ 0x1c06fd8 1 0>,
				<DCC_READ 0x1c06fdc 1 0>,
				<DCC_READ 0x1c06fe0 1 0>,
				<DCC_READ 0x1c06fe4 1 0>,
				<DCC_READ 0x1c06fe8 1 0>,
				<DCC_READ 0x1c06fec 1 0>,
				<DCC_READ 0x1c06ff0 1 0>,
				<DCC_READ 0x1c06ff4 1 0>,
				<DCC_READ 0x1c06ff8 1 0>,
				<DCC_READ 0x1c06ffc 1 0>,
				<DCC_READ 0x1c07000 1 0>,
				<DCC_READ 0x1c07004 1 0>,
				<DCC_READ 0x1c07008 1 0>,
				<DCC_READ 0x1c0700c 1 0>,
				<DCC_READ 0x1c07010 1 0>,
				<DCC_READ 0x1c07014 1 0>,
				<DCC_READ 0x1c07018 1 0>,
				<DCC_READ 0x1c0701c 1 0>,
				<DCC_READ 0x1c07020 1 0>,
				<DCC_READ 0x1c07024 1 0>,
				<DCC_READ 0x1c07028 1 0>,
				<DCC_READ 0x1c0702c 1 0>,
				<DCC_READ 0x1c07030 1 0>,
				<DCC_READ 0x1c07034 1 0>,
				<DCC_READ 0x1c07038 1 0>,
				<DCC_READ 0x1c0703c 1 0>,
				<DCC_READ 0x1c07040 1 0>,
				<DCC_READ 0x1c07044 1 0>,
				<DCC_READ 0x1c07048 1 0>,
				<DCC_READ 0x1c0704c 1 0>,
				<DCC_READ 0x1c07050 1 0>,
				<DCC_READ 0x1c07054 1 0>,
				<DCC_READ 0x1c07058 1 0>,
				<DCC_READ 0x1c0705c 1 0>,
				<DCC_READ 0x1c07060 1 0>,
				<DCC_READ 0x1c07064 1 0>,
				<DCC_READ 0x1c07068 1 0>,
				<DCC_READ 0x1c0706c 1 0>,
				<DCC_READ 0x1c07070 1 0>,
				<DCC_READ 0x1c07074 1 0>,
				<DCC_READ 0x1c07078 1 0>,
				<DCC_READ 0x1c0707c 1 0>,
				<DCC_READ 0x1c07080 1 0>,
				<DCC_READ 0x1c07084 1 0>,
				<DCC_READ 0x1c07088 1 0>,
				<DCC_READ 0x1c0708c 1 0>,
				<DCC_READ 0x1c07090 1 0>,
				<DCC_READ 0x1c07094 1 0>,
				<DCC_READ 0x1c07098 1 0>,
				<DCC_READ 0x1c0709c 1 0>,
				<DCC_READ 0x1c070a0 1 0>,
				<DCC_READ 0x1c070a4 1 0>,
				<DCC_READ 0x1c070a8 1 0>,
				<DCC_READ 0x1c070ac 1 0>,
				<DCC_READ 0x1c070b0 1 0>,
				<DCC_READ 0x1c070b4 1 0>,
				<DCC_READ 0x1c070b8 1 0>,
				<DCC_READ 0x1c070bc 1 0>,
				<DCC_READ 0x1c070c0 1 0>,
				<DCC_READ 0x1c070c4 1 0>,
				<DCC_READ 0x1c070c8 1 0>,
				<DCC_READ 0x1c070cc 1 0>,
				<DCC_READ 0x1c070d0 1 0>,
				<DCC_READ 0x1c070d4 1 0>,
				<DCC_READ 0x1c070d8 1 0>,
				<DCC_READ 0x1c070dc 1 0>,
				<DCC_READ 0x1c070e0 1 0>,
				<DCC_READ 0x1c070e4 1 0>,
				<DCC_READ 0x1c070e8 1 0>,
				<DCC_READ 0x1c070ec 1 0>,
				<DCC_READ 0x1c070f0 1 0>,
				<DCC_READ 0x1c070f4 1 0>,
				<DCC_READ 0x1c070f8 1 0>,
				<DCC_READ 0x1c070fc 1 0>,
				<DCC_READ 0x1c07100 1 0>,
				<DCC_READ 0x1c07104 1 0>,
				<DCC_READ 0x1c07108 1 0>,
				<DCC_READ 0x1c0710c 1 0>,
				<DCC_READ 0x1c07110 1 0>,
				<DCC_READ 0x1c07114 1 0>,
				<DCC_READ 0x1c07118 1 0>,
				<DCC_READ 0x1c0711c 1 0>,
				<DCC_READ 0x1c07120 1 0>,
				<DCC_READ 0x1c07124 1 0>,
				<DCC_READ 0x1c07128 1 0>,
				<DCC_READ 0x1c0712c 1 0>,
				<DCC_READ 0x1c07130 1 0>,
				<DCC_READ 0x1c07134 1 0>,
				<DCC_READ 0x1c07138 1 0>,
				<DCC_READ 0x1c0713c 1 0>,
				<DCC_READ 0x1c07140 1 0>,
				<DCC_READ 0x1c07144 1 0>,
				<DCC_READ 0x1c07148 1 0>,
				<DCC_READ 0x1c0714c 1 0>,
				<DCC_READ 0x1c07150 1 0>,
				<DCC_READ 0x1c07154 1 0>,
				<DCC_READ 0x1c07158 1 0>,
				<DCC_READ 0x1c0715c 1 0>,
				<DCC_READ 0x1c07160 1 0>,
				<DCC_READ 0x1c07164 1 0>,
				<DCC_READ 0x1c07168 1 0>,
				<DCC_READ 0x1c0716c 1 0>,
				<DCC_READ 0x1c07170 1 0>,
				<DCC_READ 0x1c07174 1 0>,
				<DCC_READ 0x1c07178 1 0>,
				<DCC_READ 0x1c0717c 1 0>,
				<DCC_READ 0x1c07180 1 0>,
				<DCC_READ 0x1c07184 1 0>,
				<DCC_READ 0x1c07188 1 0>,
				<DCC_READ 0x1c0718c 1 0>,
				<DCC_READ 0x1c07190 1 0>,
				<DCC_READ 0x1c07194 1 0>,
				<DCC_READ 0x1c07198 1 0>,
				<DCC_READ 0x1c0719c 1 0>,
				<DCC_READ 0x1c071a0 1 0>,
				<DCC_READ 0x1c071a4 1 0>,
				<DCC_READ 0x1c071a8 1 0>,
				<DCC_READ 0x1c071ac 1 0>,
				<DCC_READ 0x1c071b0 1 0>,
				<DCC_READ 0x1c071b4 1 0>,
				<DCC_READ 0x1c071b8 1 0>,
				<DCC_READ 0x1c071bc 1 0>,
				<DCC_READ 0x1c071c0 1 0>,
				<DCC_READ 0x1c071c4 1 0>,
				<DCC_READ 0x1c071c8 1 0>,
				<DCC_READ 0x1c071cc 1 0>,
				<DCC_READ 0x1c071d0 1 0>,
				<DCC_READ 0x1c071d4 1 0>,
				<DCC_READ 0x1c071d8 1 0>,
				<DCC_READ 0x1c071dc 1 0>,
				<DCC_READ 0x1c071e0 1 0>,
				<DCC_READ 0x1c071e4 1 0>,
				<DCC_READ 0x1c071e8 1 0>,
				<DCC_READ 0x1c071ec 1 0>,
				<DCC_READ 0x1c071f0 1 0>,
				<DCC_READ 0x1c071f4 1 0>,
				<DCC_READ 0x1c071f8 1 0>,
				<DCC_READ 0x1c071fc 1 0>,
				<DCC_READ 0x1c07200 1 0>,
				<DCC_READ 0x1c07204 1 0>,
				<DCC_READ 0x1c07208 1 0>,
				<DCC_READ 0x1c0720c 1 0>,
				<DCC_READ 0x1c07210 1 0>,
				<DCC_READ 0x1c07214 1 0>,
				<DCC_READ 0x1c07218 1 0>,
				<DCC_READ 0x1c0721c 1 0>,
				<DCC_READ 0x1c07220 1 0>,
				<DCC_READ 0x1c07224 1 0>,
				<DCC_READ 0x1c07228 1 0>,
				<DCC_READ 0x1c0722c 1 0>,
				<DCC_READ 0x1c07230 1 0>,
				<DCC_READ 0x1c07234 1 0>,
				<DCC_READ 0x1c07238 1 0>,
				<DCC_READ 0x1c0723c 1 0>,
				<DCC_READ 0x1c07240 1 0>,
				<DCC_READ 0x1c07244 1 0>,
				<DCC_READ 0x1c07248 1 0>,
				<DCC_READ 0x1c0724c 1 0>,
				<DCC_READ 0x1c07250 1 0>,
				<DCC_READ 0x1c07254 1 0>,
				<DCC_READ 0x1c07258 1 0>,
				<DCC_READ 0x1c0725c 1 0>,
				<DCC_READ 0x1c07260 1 0>,
				<DCC_READ 0x1c07264 1 0>,
				<DCC_READ 0x1c07268 1 0>,
				<DCC_READ 0x1c0726c 1 0>,
				<DCC_READ 0x1c07270 1 0>,
				<DCC_READ 0x1c07274 1 0>,
				<DCC_READ 0x1c07278 1 0>,
				<DCC_READ 0x1c0727c 1 0>,
				<DCC_READ 0x1c07280 1 0>,
				<DCC_READ 0x1c07284 1 0>,
				<DCC_READ 0x1c07288 1 0>,
				<DCC_READ 0x1c0728c 1 0>,
				<DCC_READ 0x1c07290 1 0>,
				<DCC_READ 0x1c07294 1 0>,
				<DCC_READ 0x1c07298 1 0>,
				<DCC_READ 0x1c0729c 1 0>,
				<DCC_READ 0x1c072a0 1 0>,
				<DCC_READ 0x1c072a4 1 0>,
				<DCC_READ 0x1c072a8 1 0>,
				<DCC_READ 0x1c072ac 1 0>,
				<DCC_READ 0x1c072b0 1 0>,
				<DCC_READ 0x1c072b4 1 0>,
				<DCC_READ 0x1c072b8 1 0>,
				<DCC_READ 0x1c072bc 1 0>,
				<DCC_READ 0x1c072c0 1 0>,
				<DCC_READ 0x1c072c4 1 0>,
				<DCC_READ 0x1c072c8 1 0>,
				<DCC_READ 0x1c072cc 1 0>,
				<DCC_READ 0x1c072d0 1 0>,
				<DCC_READ 0x1c072d4 1 0>,
				<DCC_READ 0x1c072d8 1 0>,
				<DCC_READ 0x1c072dc 1 0>,
				<DCC_READ 0x1c072e0 1 0>,
				<DCC_READ 0x1c072e4 1 0>,
				<DCC_READ 0x1c072e8 1 0>,
				<DCC_READ 0x1c072ec 1 0>,
				<DCC_READ 0x1c072f0 1 0>,
				<DCC_READ 0x1c072f4 1 0>,
				<DCC_READ 0x1c072f8 1 0>,
				<DCC_READ 0x1c072fc 1 0>,
				<DCC_READ 0x1c07300 1 0>,
				<DCC_READ 0x1c07304 1 0>,
				<DCC_READ 0x1c07308 1 0>,
				<DCC_READ 0x1c0730c 1 0>,
				<DCC_READ 0x1c07310 1 0>,
				<DCC_READ 0x1c07314 1 0>,
				<DCC_READ 0x1c07318 1 0>,
				<DCC_READ 0x1c0731c 1 0>,
				<DCC_READ 0x1c07320 1 0>,
				<DCC_READ 0x1c07324 1 0>,
				<DCC_READ 0x1c07328 1 0>,
				<DCC_READ 0x1c0732c 1 0>,
				<DCC_READ 0x1c07330 1 0>,
				<DCC_READ 0x1c07334 1 0>,
				<DCC_READ 0x1c07338 1 0>,
				<DCC_READ 0x1c0733c 1 0>,
				<DCC_READ 0x1c07340 1 0>,
				<DCC_READ 0x1c07344 1 0>,
				<DCC_READ 0x1c07348 1 0>,
				<DCC_READ 0x1c0734c 1 0>,
				<DCC_READ 0x1c07350 1 0>,
				<DCC_READ 0x1c07354 1 0>,
				<DCC_READ 0x1c07358 1 0>,
				<DCC_READ 0x1c0735c 1 0>,
				<DCC_READ 0x1c07360 1 0>,
				<DCC_READ 0x1c07364 1 0>,
				<DCC_READ 0x1c07368 1 0>,
				<DCC_READ 0x1c0736c 1 0>,
				<DCC_READ 0x1c07370 1 0>,
				<DCC_READ 0x1c07374 1 0>,
				<DCC_READ 0x1c07378 1 0>,
				<DCC_READ 0x1c0737c 1 0>,
				<DCC_READ 0x1c07380 1 0>,
				<DCC_READ 0x1c07384 1 0>,
				<DCC_READ 0x1c07388 1 0>,
				<DCC_READ 0x1c0738c 1 0>,
				<DCC_READ 0x1c07390 1 0>,
				<DCC_READ 0x1c07394 1 0>,
				<DCC_READ 0x1c07398 1 0>,
				<DCC_READ 0x1c0739c 1 0>,
				<DCC_READ 0x1c073a0 1 0>,
				<DCC_READ 0x1c073a4 1 0>,
				<DCC_READ 0x1c073a8 1 0>,
				<DCC_READ 0x1c073ac 1 0>,
				<DCC_READ 0x1c073b0 1 0>,
				<DCC_READ 0x1c073b4 1 0>,
				<DCC_READ 0x1c073b8 1 0>,
				<DCC_READ 0x1c073bc 1 0>,
				<DCC_READ 0x1c073c0 1 0>,
				<DCC_READ 0x1c073c4 1 0>,
				<DCC_READ 0x1c073c8 1 0>,
				<DCC_READ 0x1c073cc 1 0>,
				<DCC_READ 0x1c073d0 1 0>,
				<DCC_READ 0x1c073d4 1 0>,
				<DCC_READ 0x1c073d8 1 0>,
				<DCC_READ 0x1c073dc 1 0>,
				<DCC_READ 0x1c073e0 1 0>,
				<DCC_READ 0x1c073e4 1 0>,
				<DCC_READ 0x1c073e8 1 0>,
				<DCC_READ 0x1c073ec 1 0>,
				<DCC_READ 0x1c073f0 1 0>,
				<DCC_READ 0x1c073f4 1 0>,
				<DCC_READ 0x1c073f8 1 0>,
				<DCC_READ 0x1c073fc 1 0>,
				<DCC_READ 0x1c07400 1 0>,
				<DCC_READ 0x1c07404 1 0>,
				<DCC_READ 0x1c07408 1 0>,
				<DCC_READ 0x1c0740c 1 0>,
				<DCC_READ 0x1c07410 1 0>,
				<DCC_READ 0x1c07414 1 0>,
				<DCC_READ 0x1c07418 1 0>,
				<DCC_READ 0x1c0741c 1 0>,
				<DCC_READ 0x1c07420 1 0>,
				<DCC_READ 0x1c07424 1 0>,
				<DCC_READ 0x1c07428 1 0>,
				<DCC_READ 0x1c0742c 1 0>,
				<DCC_READ 0x1c07430 1 0>,
				<DCC_READ 0x1c07434 1 0>,
				<DCC_READ 0x1c07438 1 0>,
				<DCC_READ 0x1c0743c 1 0>,
				<DCC_READ 0x1c07440 1 0>,
				<DCC_READ 0x1c07444 1 0>,
				<DCC_READ 0x1c07448 1 0>,
				<DCC_READ 0x1c0744c 1 0>,
				<DCC_READ 0x1c07450 1 0>,
				<DCC_READ 0x1c07454 1 0>,
				<DCC_READ 0x1c07458 1 0>,
				<DCC_READ 0x1c0745c 1 0>,
				<DCC_READ 0x1c07460 1 0>,
				<DCC_READ 0x1c07464 1 0>,
				<DCC_READ 0x1c07468 1 0>,
				<DCC_READ 0x1c0746c 1 0>,
				<DCC_READ 0x1c07470 1 0>,
				<DCC_READ 0x1c07474 1 0>,
				<DCC_READ 0x1c07478 1 0>,
				<DCC_READ 0x1c0747c 1 0>,
				<DCC_READ 0x1c07480 1 0>,
				<DCC_READ 0x1c07484 1 0>,
				<DCC_READ 0x1c07488 1 0>,
				<DCC_READ 0x1c0748c 1 0>,
				<DCC_READ 0x1c07490 1 0>,
				<DCC_READ 0x1c07494 1 0>,
				<DCC_READ 0x1c07498 1 0>,
				<DCC_READ 0x1c0749c 1 0>,
				<DCC_READ 0x1c074a0 1 0>,
				<DCC_READ 0x1c074a4 1 0>,
				<DCC_READ 0x1c074a8 1 0>,
				<DCC_READ 0x1c074ac 1 0>,
				<DCC_READ 0x1c074b0 1 0>,
				<DCC_READ 0x1c074b4 1 0>,
				<DCC_READ 0x1c074b8 1 0>,
				<DCC_READ 0x1c074bc 1 0>,
				<DCC_READ 0x1c074c0 1 0>,
				<DCC_READ 0x1c074c4 1 0>,
				<DCC_READ 0x1c074c8 1 0>,
				<DCC_READ 0x1c074cc 1 0>,
				<DCC_READ 0x1c074d0 1 0>,
				<DCC_READ 0x1c074d4 1 0>,
				<DCC_READ 0x1c074d8 1 0>,
				<DCC_READ 0x1c074dc 1 0>,
				<DCC_READ 0x1c074e0 1 0>,
				<DCC_READ 0x1c074e4 1 0>,
				<DCC_READ 0x1c074e8 1 0>,
				<DCC_READ 0x1c074ec 1 0>,
				<DCC_READ 0x1c074f0 1 0>,
				<DCC_READ 0x1c074f4 1 0>,
				<DCC_READ 0x1c074f8 1 0>,
				<DCC_READ 0x1c074fc 1 0>,
				<DCC_READ 0x1c07500 1 0>,
				<DCC_READ 0x1c07504 1 0>,
				<DCC_READ 0x1c07508 1 0>,
				<DCC_READ 0x1c0750c 1 0>,
				<DCC_READ 0x1c07510 1 0>,
				<DCC_READ 0x1c07514 1 0>,
				<DCC_READ 0x1c07518 1 0>,
				<DCC_READ 0x1c0751c 1 0>,
				<DCC_READ 0x1c07520 1 0>,
				<DCC_READ 0x1c07524 1 0>,
				<DCC_READ 0x1c07528 1 0>,
				<DCC_READ 0x1c0752c 1 0>,
				<DCC_READ 0x1c07530 1 0>,
				<DCC_READ 0x1c07534 1 0>,
				<DCC_READ 0x1c07538 1 0>,
				<DCC_READ 0x1c0753c 1 0>,
				<DCC_READ 0x1c07540 1 0>,
				<DCC_READ 0x1c07544 1 0>,
				<DCC_READ 0x1c07548 1 0>,
				<DCC_READ 0x1c0754c 1 0>,
				<DCC_READ 0x1c07550 1 0>,
				<DCC_READ 0x1c07554 1 0>,
				<DCC_READ 0x1c07558 1 0>,
				<DCC_READ 0x1c0755c 1 0>,
				<DCC_READ 0x1c07560 1 0>,
				<DCC_READ 0x1c07564 1 0>,
				<DCC_READ 0x1c07568 1 0>,
				<DCC_READ 0x1c0756c 1 0>,
				<DCC_READ 0x1c07570 1 0>,
				<DCC_READ 0x1c07574 1 0>,
				<DCC_READ 0x1c07578 1 0>,
				<DCC_READ 0x1c0757c 1 0>,
				<DCC_READ 0x1c07580 1 0>,
				<DCC_READ 0x1c07584 1 0>,
				<DCC_READ 0x1c07588 1 0>,
				<DCC_READ 0x1c0758c 1 0>,
				<DCC_READ 0x1c07590 1 0>,
				<DCC_READ 0x1c07594 1 0>,
				<DCC_READ 0x1c07598 1 0>,
				<DCC_READ 0x1c0759c 1 0>,
				<DCC_READ 0x1c075a0 1 0>,
				<DCC_READ 0x1c075a4 1 0>,
				<DCC_READ 0x1c075a8 1 0>,
				<DCC_READ 0x1c075ac 1 0>,
				<DCC_READ 0x1c075b0 1 0>,
				<DCC_READ 0x1c075b4 1 0>,
				<DCC_READ 0x1c075b8 1 0>,
				<DCC_READ 0x1c075bc 1 0>,
				<DCC_READ 0x1c075c0 1 0>,
				<DCC_READ 0x1c075c4 1 0>,
				<DCC_READ 0x1c075c8 1 0>,
				<DCC_READ 0x1c075cc 1 0>,
				<DCC_READ 0x1c075d0 1 0>,
				<DCC_READ 0x1c075d4 1 0>,
				<DCC_READ 0x1c075d8 1 0>,
				<DCC_READ 0x1c075dc 1 0>,
				<DCC_READ 0x1c075e0 1 0>,
				<DCC_READ 0x1c075e4 1 0>,
				<DCC_READ 0x1c075e8 1 0>,
				<DCC_READ 0x1c075ec 1 0>,
				<DCC_READ 0x1c075f0 1 0>,
				<DCC_READ 0x1c075f4 1 0>,
				<DCC_READ 0x1c075f8 1 0>,
				<DCC_READ 0x1c075fc 1 0>,
				<DCC_READ 0x1c07600 1 0>,
				<DCC_READ 0x1c07604 1 0>,
				<DCC_READ 0x1c07608 1 0>,
				<DCC_READ 0x1c0760c 1 0>,
				<DCC_READ 0x1c07610 1 0>,
				<DCC_READ 0x1c07614 1 0>,
				<DCC_READ 0x1c07618 1 0>,
				<DCC_READ 0x1c0761c 1 0>,
				<DCC_READ 0x1c07620 1 0>,
				<DCC_READ 0x1c07624 1 0>,
				<DCC_READ 0x1c07628 1 0>,
				<DCC_READ 0x1c0762c 1 0>,
				<DCC_READ 0x1c07630 1 0>,
				<DCC_READ 0x1c07634 1 0>,
				<DCC_READ 0x1c07638 1 0>,
				<DCC_READ 0x1c0763c 1 0>,
				<DCC_READ 0x1c07640 1 0>,
				<DCC_READ 0x1c07644 1 0>,
				<DCC_READ 0x1c07648 1 0>,
				<DCC_READ 0x1c0764c 1 0>,
				<DCC_READ 0x1c07650 1 0>,
				<DCC_READ 0x1c07654 1 0>,
				<DCC_READ 0x1c07658 1 0>,
				<DCC_READ 0x1c0765c 1 0>,
				<DCC_READ 0x1c07660 1 0>,
				<DCC_READ 0x1c07664 1 0>,
				<DCC_READ 0x1c07668 1 0>,
				<DCC_READ 0x1c0766c 1 0>,
				<DCC_READ 0x1c07670 1 0>,
				<DCC_READ 0x1c07674 1 0>,
				<DCC_READ 0x1c07678 1 0>,
				<DCC_READ 0x1c0767c 1 0>,
				<DCC_READ 0x1c07680 1 0>,
				<DCC_READ 0x1c07684 1 0>,
				<DCC_READ 0x1c07688 1 0>,
				<DCC_READ 0x1c0768c 1 0>,
				<DCC_READ 0x1c07690 1 0>,
				<DCC_READ 0x1c07694 1 0>,
				<DCC_READ 0x1c07698 1 0>,
				<DCC_READ 0x1c0769c 1 0>,
				<DCC_READ 0x1c076a0 1 0>,
				<DCC_READ 0x1c076a4 1 0>,
				<DCC_READ 0x1c076a8 1 0>,
				<DCC_READ 0x1c076ac 1 0>,
				<DCC_READ 0x1c076b0 1 0>,
				<DCC_READ 0x1c076b4 1 0>,
				<DCC_READ 0x1c076b8 1 0>,
				<DCC_READ 0x1c076bc 1 0>,
				<DCC_READ 0x1c076c0 1 0>,
				<DCC_READ 0x1c076c4 1 0>,
				<DCC_READ 0x1c076c8 1 0>,
				<DCC_READ 0x1c076cc 1 0>,
				<DCC_READ 0x1c076d0 1 0>,
				<DCC_READ 0x1c076d4 1 0>,
				<DCC_READ 0x1c076d8 1 0>,
				<DCC_READ 0x1c076dc 1 0>,
				<DCC_READ 0x1c076e0 1 0>,
				<DCC_READ 0x1c076e4 1 0>,
				<DCC_READ 0x1c076e8 1 0>,
				<DCC_READ 0x1c076ec 1 0>,
				<DCC_READ 0x1c076f0 1 0>,
				<DCC_READ 0x1c076f4 1 0>,
				<DCC_READ 0x1c076f8 1 0>,
				<DCC_READ 0x1c076fc 1 0>,
				<DCC_READ 0x1c07700 1 0>,
				<DCC_READ 0x1c07704 1 0>,
				<DCC_READ 0x1c07708 1 0>,
				<DCC_READ 0x1c0770c 1 0>,
				<DCC_READ 0x1c07710 1 0>,
				<DCC_READ 0x1c07714 1 0>,
				<DCC_READ 0x1c07718 1 0>,
				<DCC_READ 0x1c0771c 1 0>,
				<DCC_READ 0x1c07720 1 0>,
				<DCC_READ 0x1c07724 1 0>,
				<DCC_READ 0x1c07728 1 0>,
				<DCC_READ 0x1c0772c 1 0>,
				<DCC_READ 0x1c07730 1 0>,
				<DCC_READ 0x1c07734 1 0>,
				<DCC_READ 0x1c07738 1 0>,
				<DCC_READ 0x1c0773c 1 0>,
				<DCC_READ 0x1c07740 1 0>,
				<DCC_READ 0x1c07744 1 0>,
				<DCC_READ 0x1c07748 1 0>,
				<DCC_READ 0x1c0774c 1 0>,
				<DCC_READ 0x1c07750 1 0>,
				<DCC_READ 0x1c07754 1 0>,
				<DCC_READ 0x1c07758 1 0>,
				<DCC_READ 0x1c0775c 1 0>,
				<DCC_READ 0x1c07760 1 0>,
				<DCC_READ 0x1c07764 1 0>,
				<DCC_READ 0x1c07768 1 0>,
				<DCC_READ 0x1c0776c 1 0>,
				<DCC_READ 0x1c07770 1 0>,
				<DCC_READ 0x1c07774 1 0>,
				<DCC_READ 0x1c07778 1 0>,
				<DCC_READ 0x1c0777c 1 0>,
				<DCC_READ 0x1c07780 1 0>,
				<DCC_READ 0x1c07784 1 0>,
				<DCC_READ 0x1c07788 1 0>,
				<DCC_READ 0x1c0778c 1 0>,
				<DCC_READ 0x1c07790 1 0>,
				<DCC_READ 0x1c07794 1 0>,
				<DCC_READ 0x1c07798 1 0>,
				<DCC_READ 0x1c0779c 1 0>,
				<DCC_READ 0x1c077a0 1 0>,
				<DCC_READ 0x1c077a4 1 0>,
				<DCC_READ 0x1c077a8 1 0>,
				<DCC_READ 0x1c077ac 1 0>,
				<DCC_READ 0x1c077b0 1 0>,
				<DCC_READ 0x1c077b4 1 0>,
				<DCC_READ 0x1c077b8 1 0>,
				<DCC_READ 0x1c077bc 1 0>,
				<DCC_READ 0x1c077c0 1 0>,
				<DCC_READ 0x1c077c4 1 0>,
				<DCC_READ 0x1c077c8 1 0>,
				<DCC_READ 0x1c077cc 1 0>,
				<DCC_READ 0x1c077d0 1 0>,
				<DCC_READ 0x1c077d4 1 0>,
				<DCC_READ 0x1c077d8 1 0>,
				<DCC_READ 0x1c077dc 1 0>,
				<DCC_READ 0x1c077e0 1 0>,
				<DCC_READ 0x1c077e4 1 0>,
				<DCC_READ 0x1c077e8 1 0>,
				<DCC_READ 0x1c077ec 1 0>,
				<DCC_READ 0x1c077f0 1 0>,
				<DCC_READ 0x1c077f4 1 0>,
				<DCC_READ 0x1c077f8 1 0>,
				<DCC_READ 0x1c077fc 1 0>,
				<DCC_READ 0x1c07800 1 0>,
				<DCC_READ 0x1c07804 1 0>,
				<DCC_READ 0x1c07808 1 0>,
				<DCC_READ 0x1c0780c 1 0>,
				<DCC_READ 0x1c07810 1 0>,
				<DCC_READ 0x1c07814 1 0>,
				<DCC_READ 0x1c07818 1 0>,
				<DCC_READ 0x1c0781c 1 0>,
				<DCC_READ 0x1c07820 1 0>,
				<DCC_READ 0x1c07824 1 0>,
				<DCC_READ 0x1c07828 1 0>,
				<DCC_READ 0x1c0782c 1 0>,
				<DCC_READ 0x1c07830 1 0>,
				<DCC_READ 0x1c07834 1 0>,
				<DCC_READ 0x1c07838 1 0>,
				<DCC_READ 0x1c0783c 1 0>,
				<DCC_READ 0x1c07840 1 0>,
				<DCC_READ 0x1c07844 1 0>,
				<DCC_READ 0x1c07848 1 0>,
				<DCC_READ 0x1c0784c 1 0>,
				<DCC_READ 0x1c07850 1 0>,
				<DCC_READ 0x1c07854 1 0>,
				<DCC_READ 0x1c07858 1 0>,
				<DCC_READ 0x1c0785c 1 0>,
				<DCC_READ 0x1c07860 1 0>,
				<DCC_READ 0x1c07864 1 0>,
				<DCC_READ 0x1c07868 1 0>,
				<DCC_READ 0x1c0786c 1 0>,
				<DCC_READ 0x1c07870 1 0>,
				<DCC_READ 0x1c07874 1 0>,
				<DCC_READ 0x1c07878 1 0>,
				<DCC_READ 0x1c0787c 1 0>,
				<DCC_READ 0x1c07880 1 0>,
				<DCC_READ 0x1c07884 1 0>,
				<DCC_READ 0x1c07888 1 0>,
				<DCC_READ 0x1c0788c 1 0>,
				<DCC_READ 0x1c07890 1 0>,
				<DCC_READ 0x1c07894 1 0>,
				<DCC_READ 0x1c07898 1 0>,
				<DCC_READ 0x1c0789c 1 0>,
				<DCC_READ 0x1c078a0 1 0>,
				<DCC_READ 0x1c078a4 1 0>,
				<DCC_READ 0x1c078a8 1 0>,
				<DCC_READ 0x1c078ac 1 0>,
				<DCC_READ 0x1c078b0 1 0>,
				<DCC_READ 0x1c078b4 1 0>,
				<DCC_READ 0x1c078b8 1 0>,
				<DCC_READ 0x1c078bc 1 0>,
				<DCC_READ 0x1c078c0 1 0>,
				<DCC_READ 0x1c078c4 1 0>,
				<DCC_READ 0x1c078c8 1 0>,
				<DCC_READ 0x1c078cc 1 0>,
				<DCC_READ 0x1c078d0 1 0>,
				<DCC_READ 0x1c078d4 1 0>,
				<DCC_READ 0x1c078d8 1 0>,
				<DCC_READ 0x1c078dc 1 0>,
				<DCC_READ 0x1c078e0 1 0>,
				<DCC_READ 0x1c078e4 1 0>,
				<DCC_READ 0x1c078e8 1 0>,
				<DCC_READ 0x1c078ec 1 0>,
				<DCC_READ 0x1c078f0 1 0>,
				<DCC_READ 0x1c078f4 1 0>,
				<DCC_READ 0x1c078f8 1 0>,
				<DCC_READ 0x1c078fc 1 0>,
				<DCC_READ 0x1c07900 1 0>,
				<DCC_READ 0x1c07904 1 0>,
				<DCC_READ 0x1c07908 1 0>,
				<DCC_READ 0x1c0790c 1 0>,
				<DCC_READ 0x1c07910 1 0>,
				<DCC_READ 0x1c07914 1 0>,
				<DCC_READ 0x1c07918 1 0>,
				<DCC_READ 0x1c0791c 1 0>,
				<DCC_READ 0x1c07920 1 0>,
				<DCC_READ 0x1c07924 1 0>,
				<DCC_READ 0x1c07928 1 0>,
				<DCC_READ 0x1c0792c 1 0>,
				<DCC_READ 0x1c07930 1 0>,
				<DCC_READ 0x1c07934 1 0>,
				<DCC_READ 0x1c07938 1 0>,
				<DCC_READ 0x1c0793c 1 0>,
				<DCC_READ 0x1c07940 1 0>,
				<DCC_READ 0x1c07944 1 0>,
				<DCC_READ 0x1c07948 1 0>,
				<DCC_READ 0x1c0794c 1 0>,
				<DCC_READ 0x1c07950 1 0>,
				<DCC_READ 0x1c07954 1 0>,
				<DCC_READ 0x1c07958 1 0>,
				<DCC_READ 0x1c0795c 1 0>,
				<DCC_READ 0x1c07960 1 0>,
				<DCC_READ 0x1c07964 1 0>,
				<DCC_READ 0x1c07968 1 0>,
				<DCC_READ 0x1c0796c 1 0>,
				<DCC_READ 0x1c07970 1 0>,
				<DCC_READ 0x1c07974 1 0>,
				<DCC_READ 0x1c07978 1 0>,
				<DCC_READ 0x1c0797c 1 0>,
				<DCC_READ 0x1c07980 1 0>,
				<DCC_READ 0x1c07984 1 0>,
				<DCC_READ 0x1c07988 1 0>,
				<DCC_READ 0x1c0798c 1 0>,
				<DCC_READ 0x1c07990 1 0>,
				<DCC_READ 0x1c07994 1 0>,
				<DCC_READ 0x1c07998 1 0>,
				<DCC_READ 0x1c0799c 1 0>,
				<DCC_READ 0x1c079a0 1 0>,
				<DCC_READ 0x1c079a4 1 0>,
				<DCC_READ 0x1c079a8 1 0>,
				<DCC_READ 0x1c079ac 1 0>,
				<DCC_READ 0x1c079b0 1 0>,
				<DCC_READ 0x1c079b4 1 0>,
				<DCC_READ 0x1c079b8 1 0>,
				<DCC_READ 0x1c079bc 1 0>,
				<DCC_READ 0x1c079c0 1 0>,
				<DCC_READ 0x1c079c4 1 0>,
				<DCC_READ 0x1c079c8 1 0>,
				<DCC_READ 0x1c079cc 1 0>,
				<DCC_READ 0x1c079d0 1 0>,
				<DCC_READ 0x1c079d4 1 0>,
				<DCC_READ 0x1c079d8 1 0>,
				<DCC_READ 0x1c079dc 1 0>,
				<DCC_READ 0x1c079e0 1 0>,
				<DCC_READ 0x1c079e4 1 0>,
				<DCC_READ 0x1c079e8 1 0>,
				<DCC_READ 0x1c079ec 1 0>,
				<DCC_READ 0x1c079f0 1 0>,
				<DCC_READ 0x1c079f4 1 0>,
				<DCC_READ 0x1c079f8 1 0>,
				<DCC_READ 0x1c079fc 1 0>,
				<DCC_READ 0x1c00000 1 0>,
				<DCC_READ 0x1c00004 1 0>,
				<DCC_READ 0x1c00008 1 0>,
				<DCC_READ 0x1c0000c 1 0>,
				<DCC_READ 0x1c00010 1 0>,
				<DCC_READ 0x1c00014 1 0>,
				<DCC_READ 0x1c00018 1 0>,
				<DCC_READ 0x1c0001c 1 0>,
				<DCC_READ 0x1c00020 1 0>,
				<DCC_READ 0x1c00024 1 0>,
				<DCC_READ 0x1c00028 1 0>,
				<DCC_READ 0x1c0002c 1 0>,
				<DCC_READ 0x1c00030 1 0>,
				<DCC_READ 0x1c00034 1 0>,
				<DCC_READ 0x1c00038 1 0>,
				<DCC_READ 0x1c0003c 1 0>,
				<DCC_READ 0x1c00040 1 0>,
				<DCC_READ 0x1c00044 1 0>,
				<DCC_READ 0x1c00048 1 0>,
				<DCC_READ 0x1c0004c 1 0>,
				<DCC_READ 0x1c00050 1 0>,
				<DCC_READ 0x1c00054 1 0>,
				<DCC_READ 0x1c00058 1 0>,
				<DCC_READ 0x1c0005c 1 0>,
				<DCC_READ 0x1c00060 1 0>,
				<DCC_READ 0x1c00064 1 0>,
				<DCC_READ 0x1c00068 1 0>,
				<DCC_READ 0x1c0006c 1 0>,
				<DCC_READ 0x1c00070 1 0>,
				<DCC_READ 0x1c00074 1 0>,
				<DCC_READ 0x1c00078 1 0>,
				<DCC_READ 0x1c0007c 1 0>,
				<DCC_READ 0x1c00080 1 0>,
				<DCC_READ 0x1c00084 1 0>,
				<DCC_READ 0x1c00088 1 0>,
				<DCC_READ 0x1c0008c 1 0>,
				<DCC_READ 0x1c00090 1 0>,
				<DCC_READ 0x1c00094 1 0>,
				<DCC_READ 0x1c00098 1 0>,
				<DCC_READ 0x1c0009c 1 0>,
				<DCC_READ 0x1c000a0 1 0>,
				<DCC_READ 0x1c000a4 1 0>,
				<DCC_READ 0x1c000a8 1 0>,
				<DCC_READ 0x1c000ac 1 0>,
				<DCC_READ 0x1c000b0 1 0>,
				<DCC_READ 0x1c000b4 1 0>,
				<DCC_READ 0x1c000b8 1 0>,
				<DCC_READ 0x1c000bc 1 0>,
				<DCC_READ 0x1c000c0 1 0>,
				<DCC_READ 0x1c000c4 1 0>,
				<DCC_READ 0x1c000c8 1 0>,
				<DCC_READ 0x1c000cc 1 0>,
				<DCC_READ 0x1c000d0 1 0>,
				<DCC_READ 0x1c000d4 1 0>,
				<DCC_READ 0x1c000d8 1 0>,
				<DCC_READ 0x1c000dc 1 0>,
				<DCC_READ 0x1c000e0 1 0>,
				<DCC_READ 0x1c000e4 1 0>,
				<DCC_READ 0x1c000e8 1 0>,
				<DCC_READ 0x1c000ec 1 0>,
				<DCC_READ 0x1c000f0 1 0>,
				<DCC_READ 0x1c000f4 1 0>,
				<DCC_READ 0x1c000f8 1 0>,
				<DCC_READ 0x1c000fc 1 0>,
				<DCC_READ 0x1c00100 1 0>,
				<DCC_READ 0x1c00104 1 0>,
				<DCC_READ 0x1c00108 1 0>,
				<DCC_READ 0x1c0010c 1 0>,
				<DCC_READ 0x1c00110 1 0>,
				<DCC_READ 0x1c00114 1 0>,
				<DCC_READ 0x1c00118 1 0>,
				<DCC_READ 0x1c0011c 1 0>,
				<DCC_READ 0x1c00120 1 0>,
				<DCC_READ 0x1c00124 1 0>,
				<DCC_READ 0x1c00128 1 0>,
				<DCC_READ 0x1c0012c 1 0>,
				<DCC_READ 0x1c00130 1 0>,
				<DCC_READ 0x1c00134 1 0>,
				<DCC_READ 0x1c00138 1 0>,
				<DCC_READ 0x1c0013c 1 0>,
				<DCC_READ 0x1c00140 1 0>,
				<DCC_READ 0x1c00144 1 0>,
				<DCC_READ 0x1c00148 1 0>,
				<DCC_READ 0x1c0014c 1 0>,
				<DCC_READ 0x1c00150 1 0>,
				<DCC_READ 0x1c00154 1 0>,
				<DCC_READ 0x1c00158 1 0>,
				<DCC_READ 0x1c0015c 1 0>,
				<DCC_READ 0x1c00160 1 0>,
				<DCC_READ 0x1c00164 1 0>,
				<DCC_READ 0x1c00168 1 0>,
				<DCC_READ 0x1c0016c 1 0>,
				<DCC_READ 0x1c00170 1 0>,
				<DCC_READ 0x1c00174 1 0>,
				<DCC_READ 0x1c00178 1 0>,
				<DCC_READ 0x1c0017c 1 0>,
				<DCC_READ 0x1c00180 1 0>,
				<DCC_READ 0x1c00184 1 0>,
				<DCC_READ 0x1c00188 1 0>,
				<DCC_READ 0x1c0018c 1 0>,
				<DCC_READ 0x1c00190 1 0>,
				<DCC_READ 0x1c00194 1 0>,
				<DCC_READ 0x1c00198 1 0>,
				<DCC_READ 0x1c0019c 1 0>,
				<DCC_READ 0x1c001a0 1 0>,
				<DCC_READ 0x1c001a4 1 0>,
				<DCC_READ 0x1c001a8 1 0>,
				<DCC_READ 0x1c001ac 1 0>,
				<DCC_READ 0x1c001b0 1 0>,
				<DCC_READ 0x1c001b4 1 0>,
				<DCC_READ 0x1c001b8 1 0>,
				<DCC_READ 0x1c001bc 1 0>,
				<DCC_READ 0x1c001c0 1 0>,
				<DCC_READ 0x1c001c4 1 0>,
				<DCC_READ 0x1c001c8 1 0>,
				<DCC_READ 0x1c001cc 1 0>,
				<DCC_READ 0x1c001d0 1 0>,
				<DCC_READ 0x1c001d4 1 0>,
				<DCC_READ 0x1c001d8 1 0>,
				<DCC_READ 0x1c001dc 1 0>,
				<DCC_READ 0x1c001e0 1 0>,
				<DCC_READ 0x1c001e4 1 0>,
				<DCC_READ 0x1c001e8 1 0>,
				<DCC_READ 0x1c001ec 1 0>,
				<DCC_READ 0x1c001f0 1 0>,
				<DCC_READ 0x1c001f4 1 0>,
				<DCC_READ 0x1c001f8 1 0>,
				<DCC_READ 0x1c001fc 1 0>,
				<DCC_READ 0x1c00200 1 0>,
				<DCC_READ 0x1c00204 1 0>,
				<DCC_READ 0x1c00208 1 0>,
				<DCC_READ 0x1c0020c 1 0>,
				<DCC_READ 0x1c00210 1 0>,
				<DCC_READ 0x1c00214 1 0>,
				<DCC_READ 0x1c00218 1 0>,
				<DCC_READ 0x1c0021c 1 0>,
				<DCC_READ 0x1c00220 1 0>,
				<DCC_READ 0x1c00224 1 0>,
				<DCC_READ 0x1c00228 1 0>,
				<DCC_READ 0x1c0022c 1 0>,
				<DCC_READ 0x1c00230 1 0>,
				<DCC_READ 0x1c00234 1 0>,
				<DCC_READ 0x1c00238 1 0>,
				<DCC_READ 0x1c0023c 1 0>,
				<DCC_READ 0x1c00240 1 0>,
				<DCC_READ 0x1c00244 1 0>,
				<DCC_READ 0x1c00248 1 0>,
				<DCC_READ 0x1c0024c 1 0>,
				<DCC_READ 0x1c00250 1 0>,
				<DCC_READ 0x1c00254 1 0>,
				<DCC_READ 0x1c00258 1 0>,
				<DCC_READ 0x1c0025c 1 0>,
				<DCC_READ 0x1c00260 1 0>,
				<DCC_READ 0x1c00264 1 0>,
				<DCC_READ 0x1c00268 1 0>,
				<DCC_READ 0x1c0026c 1 0>,
				<DCC_READ 0x1c00270 1 0>,
				<DCC_READ 0x1c00274 1 0>,
				<DCC_READ 0x1c00278 1 0>,
				<DCC_READ 0x1c0027c 1 0>,
				<DCC_READ 0x1c00280 1 0>,
				<DCC_READ 0x1c00284 1 0>,
				<DCC_READ 0x1c00288 1 0>,
				<DCC_READ 0x1c0028c 1 0>,
				<DCC_READ 0x1c00290 1 0>,
				<DCC_READ 0x1c00294 1 0>,
				<DCC_READ 0x1c00298 1 0>,
				<DCC_READ 0x1c0029c 1 0>,
				<DCC_READ 0x1c002a0 1 0>,
				<DCC_READ 0x1c002a4 1 0>,
				<DCC_READ 0x1c002a8 1 0>,
				<DCC_READ 0x1c002ac 1 0>,
				<DCC_READ 0x1c002b0 1 0>,
				<DCC_READ 0x1c002b4 1 0>,
				<DCC_READ 0x1c002b8 1 0>,
				<DCC_READ 0x1c002bc 1 0>,
				<DCC_READ 0x1c002c0 1 0>,
				<DCC_READ 0x1c002c4 1 0>,
				<DCC_READ 0x1c002c8 1 0>,
				<DCC_READ 0x1c002cc 1 0>,
				<DCC_READ 0x1c002d0 1 0>,
				<DCC_READ 0x1c002d4 1 0>,
				<DCC_READ 0x1c002d8 1 0>,
				<DCC_READ 0x1c002dc 1 0>,
				<DCC_READ 0x1c002e0 1 0>,
				<DCC_READ 0x1c002e4 1 0>,
				<DCC_READ 0x1c002e8 1 0>,
				<DCC_READ 0x1c002ec 1 0>,
				<DCC_READ 0x1c002f0 1 0>,
				<DCC_READ 0x1c002f4 1 0>,
				<DCC_READ 0x1c002f8 1 0>,
				<DCC_READ 0x1c002fc 1 0>,
				<DCC_READ 0x1c00300 1 0>,
				<DCC_READ 0x1c00304 1 0>,
				<DCC_READ 0x1c00308 1 0>,
				<DCC_READ 0x1c0030c 1 0>,
				<DCC_READ 0x1c00310 1 0>,
				<DCC_READ 0x1c00314 1 0>,
				<DCC_READ 0x1c00318 1 0>,
				<DCC_READ 0x1c0031c 1 0>,
				<DCC_READ 0x1c00320 1 0>,
				<DCC_READ 0x1c00324 1 0>,
				<DCC_READ 0x1c00328 1 0>,
				<DCC_READ 0x1c0032c 1 0>,
				<DCC_READ 0x1c00330 1 0>,
				<DCC_READ 0x1c00334 1 0>,
				<DCC_READ 0x1c00338 1 0>,
				<DCC_READ 0x1c0033c 1 0>,
				<DCC_READ 0x1c00340 1 0>,
				<DCC_READ 0x1c00344 1 0>,
				<DCC_READ 0x1c00348 1 0>,
				<DCC_READ 0x1c0034c 1 0>,
				<DCC_READ 0x1c00350 1 0>,
				<DCC_READ 0x1c00354 1 0>,
				<DCC_READ 0x1c00358 1 0>,
				<DCC_READ 0x1c0035c 1 0>,
				<DCC_READ 0x1c00360 1 0>,
				<DCC_READ 0x1c00364 1 0>,
				<DCC_READ 0x1c00368 1 0>,
				<DCC_READ 0x1c0036c 1 0>,
				<DCC_READ 0x1c00370 1 0>,
				<DCC_READ 0x1c00374 1 0>,
				<DCC_READ 0x1c00378 1 0>,
				<DCC_READ 0x1c0037c 1 0>,
				<DCC_READ 0x1c00380 1 0>,
				<DCC_READ 0x1c00384 1 0>,
				<DCC_READ 0x1c00388 1 0>,
				<DCC_READ 0x1c0038c 1 0>,
				<DCC_READ 0x1c00390 1 0>,
				<DCC_READ 0x1c00394 1 0>,
				<DCC_READ 0x1c00398 1 0>,
				<DCC_READ 0x1c0039c 1 0>,
				<DCC_READ 0x1c003a0 1 0>,
				<DCC_READ 0x1c003a4 1 0>,
				<DCC_READ 0x1c003a8 1 0>,
				<DCC_READ 0x1c003ac 1 0>,
				<DCC_READ 0x1c003b0 1 0>,
				<DCC_READ 0x1c003b4 1 0>,
				<DCC_READ 0x1c003b8 1 0>,
				<DCC_READ 0x1c003bc 1 0>,
				<DCC_READ 0x1c003c0 1 0>,
				<DCC_READ 0x1c003c4 1 0>,
				<DCC_READ 0x1c003c8 1 0>,
				<DCC_READ 0x1c003cc 1 0>,
				<DCC_READ 0x1c003d0 1 0>,
				<DCC_READ 0x1c003d4 1 0>,
				<DCC_READ 0x1c003d8 1 0>,
				<DCC_READ 0x1c003dc 1 0>,
				<DCC_READ 0x1c003e0 1 0>,
				<DCC_READ 0x1c003e4 1 0>,
				<DCC_READ 0x1c003e8 1 0>,
				<DCC_READ 0x1c003ec 1 0>,
				<DCC_READ 0x1c003f0 1 0>,
				<DCC_READ 0x1c003f4 1 0>,
				<DCC_READ 0x1c003f8 1 0>,
				<DCC_READ 0x1c003fc 1 0>,
				<DCC_READ 0x1c00400 1 0>,
				<DCC_READ 0x1c00404 1 0>,
				<DCC_READ 0x1c00408 1 0>,
				<DCC_READ 0x1c0040c 1 0>,
				<DCC_READ 0x1c00410 1 0>,
				<DCC_READ 0x1c00414 1 0>,
				<DCC_READ 0x1c00418 1 0>,
				<DCC_READ 0x1c0041c 1 0>,
				<DCC_READ 0x1c00420 1 0>,
				<DCC_READ 0x1c00424 1 0>,
				<DCC_READ 0x1c00428 1 0>,
				<DCC_READ 0x1c0042c 1 0>,
				<DCC_READ 0x1c00430 1 0>,
				<DCC_READ 0x1c00434 1 0>,
				<DCC_READ 0x1c00438 1 0>,
				<DCC_READ 0x1c0043c 1 0>,
				<DCC_READ 0x1c00440 1 0>,
				<DCC_READ 0x1c00444 1 0>,
				<DCC_READ 0x1c00448 1 0>,
				<DCC_READ 0x1c0044c 1 0>,
				<DCC_READ 0x1c00450 1 0>,
				<DCC_READ 0x1c00454 1 0>,
				<DCC_READ 0x1c00458 1 0>,
				<DCC_READ 0x1c0045c 1 0>,
				<DCC_READ 0x1c00460 1 0>,
				<DCC_READ 0x1c00464 1 0>,
				<DCC_READ 0x1c00468 1 0>,
				<DCC_READ 0x1c0046c 1 0>,
				<DCC_READ 0x1c00470 1 0>,
				<DCC_READ 0x1c00474 1 0>,
				<DCC_READ 0x1c00478 1 0>,
				<DCC_READ 0x1c0047c 1 0>,
				<DCC_READ 0x1c00480 1 0>,
				<DCC_READ 0x1c00484 1 0>,
				<DCC_READ 0x1c00488 1 0>,
				<DCC_READ 0x1c0048c 1 0>,
				<DCC_READ 0x1c00490 1 0>,
				<DCC_READ 0x1c00494 1 0>,
				<DCC_READ 0x1c00498 1 0>,
				<DCC_READ 0x1c0049c 1 0>,
				<DCC_READ 0x1c004a0 1 0>,
				<DCC_READ 0x1c004a4 1 0>,
				<DCC_READ 0x1c004a8 1 0>,
				<DCC_READ 0x1c004ac 1 0>,
				<DCC_READ 0x1c004b0 1 0>,
				<DCC_READ 0x1c004b4 1 0>,
				<DCC_READ 0x1c004b8 1 0>,
				<DCC_READ 0x1c004bc 1 0>,
				<DCC_READ 0x1c004c0 1 0>,
				<DCC_READ 0x1c004c4 1 0>,
				<DCC_READ 0x1c004c8 1 0>,
				<DCC_READ 0x1c004cc 1 0>,
				<DCC_READ 0x1c004d0 1 0>,
				<DCC_READ 0x1c004d4 1 0>,
				<DCC_READ 0x1c004d8 1 0>,
				<DCC_READ 0x1c004dc 1 0>,
				<DCC_READ 0x1c004e0 1 0>,
				<DCC_READ 0x1c004e4 1 0>,
				<DCC_READ 0x1c004e8 1 0>,
				<DCC_READ 0x1c004ec 1 0>,
				<DCC_READ 0x1c004f0 1 0>,
				<DCC_READ 0x1c004f4 1 0>,
				<DCC_READ 0x1c004f8 1 0>,
				<DCC_READ 0x1c004fc 1 0>,
				<DCC_READ 0x1c00500 1 0>,
				<DCC_READ 0x1c00504 1 0>,
				<DCC_READ 0x1c00508 1 0>,
				<DCC_READ 0x1c0050c 1 0>,
				<DCC_READ 0x1c00510 1 0>,
				<DCC_READ 0x1c00514 1 0>,
				<DCC_READ 0x1c00518 1 0>,
				<DCC_READ 0x1c0051c 1 0>,
				<DCC_READ 0x1c00520 1 0>,
				<DCC_READ 0x1c00524 1 0>,
				<DCC_READ 0x1c00528 1 0>,
				<DCC_READ 0x1c0052c 1 0>,
				<DCC_READ 0x1c00530 1 0>,
				<DCC_READ 0x1c00534 1 0>,
				<DCC_READ 0x1c00538 1 0>,
				<DCC_READ 0x1c0053c 1 0>,
				<DCC_READ 0x1c00540 1 0>,
				<DCC_READ 0x1c00544 1 0>,
				<DCC_READ 0x1c00548 1 0>,
				<DCC_READ 0x1c0054c 1 0>,
				<DCC_READ 0x1c00550 1 0>,
				<DCC_READ 0x1c00554 1 0>,
				<DCC_READ 0x1c00558 1 0>,
				<DCC_READ 0x1c0055c 1 0>,
				<DCC_READ 0x1c00560 1 0>,
				<DCC_READ 0x1c00564 1 0>,
				<DCC_READ 0x1c00568 1 0>,
				<DCC_READ 0x1c0056c 1 0>,
				<DCC_READ 0x1c00570 1 0>,
				<DCC_READ 0x1c00574 1 0>,
				<DCC_READ 0x1c00578 1 0>,
				<DCC_READ 0x1c0057c 1 0>,
				<DCC_READ 0x1c00580 1 0>,
				<DCC_READ 0x1c00584 1 0>,
				<DCC_READ 0x1c00588 1 0>,
				<DCC_READ 0x1c0058c 1 0>,
				<DCC_READ 0x1c00590 1 0>,
				<DCC_READ 0x1c00594 1 0>,
				<DCC_READ 0x1c00598 1 0>,
				<DCC_READ 0x1c0059c 1 0>,
				<DCC_READ 0x1c005a0 1 0>,
				<DCC_READ 0x1c005a4 1 0>,
				<DCC_READ 0x1c005a8 1 0>,
				<DCC_READ 0x1c005ac 1 0>,
				<DCC_READ 0x1c005b0 1 0>,
				<DCC_READ 0x1c005b4 1 0>,
				<DCC_READ 0x1c005b8 1 0>,
				<DCC_READ 0x1c005bc 1 0>,
				<DCC_READ 0x1c005c0 1 0>,
				<DCC_READ 0x1c005c4 1 0>,
				<DCC_READ 0x1c005c8 1 0>,
				<DCC_READ 0x1c005cc 1 0>,
				<DCC_READ 0x1c005d0 1 0>,
				<DCC_READ 0x1c005d4 1 0>,
				<DCC_READ 0x1c005d8 1 0>,
				<DCC_READ 0x1c005dc 1 0>,
				<DCC_READ 0x1c005e0 1 0>,
				<DCC_READ 0x1c005e4 1 0>,
				<DCC_READ 0x1c005e8 1 0>,
				<DCC_READ 0x1c005ec 1 0>,
				<DCC_READ 0x1c005f0 1 0>,
				<DCC_READ 0x1c005f4 1 0>,
				<DCC_READ 0x1c005f8 1 0>,
				<DCC_READ 0x1c005fc 1 0>,
				<DCC_READ 0x1c00600 1 0>,
				<DCC_READ 0x1c00604 1 0>,
				<DCC_READ 0x1c00608 1 0>,
				<DCC_READ 0x1c0060c 1 0>,
				<DCC_READ 0x1c00610 1 0>,
				<DCC_READ 0x1c00614 1 0>,
				<DCC_READ 0x1c00618 1 0>,
				<DCC_READ 0x1c0061c 1 0>,
				<DCC_READ 0x1c00620 1 0>,
				<DCC_READ 0x1c00624 1 0>,
				<DCC_READ 0x1c00628 1 0>,
				<DCC_READ 0x1c0062c 1 0>,
				<DCC_READ 0x1c00630 1 0>,
				<DCC_READ 0x1c00634 1 0>,
				<DCC_READ 0x1c00638 1 0>,
				<DCC_READ 0x1c0063c 1 0>,
				<DCC_READ 0x1c00640 1 0>,
				<DCC_READ 0x1c00644 1 0>,
				<DCC_READ 0x1c00648 1 0>,
				<DCC_READ 0x1c0064c 1 0>,
				<DCC_READ 0x1c00650 1 0>,
				<DCC_READ 0x1c00654 1 0>,
				<DCC_READ 0x1c00658 1 0>,
				<DCC_READ 0x1c0065c 1 0>,
				<DCC_READ 0x1c00660 1 0>,
				<DCC_READ 0x1c00664 1 0>,
				<DCC_READ 0x1c00668 1 0>,
				<DCC_READ 0x1c0066c 1 0>,
				<DCC_READ 0x1c00670 1 0>,
				<DCC_READ 0x1c00674 1 0>,
				<DCC_READ 0x1c00678 1 0>,
				<DCC_READ 0x1c0067c 1 0>,
				<DCC_READ 0x1c00680 1 0>,
				<DCC_READ 0x1c00684 1 0>,
				<DCC_READ 0x1c00688 1 0>,
				<DCC_READ 0x1c0068c 1 0>,
				<DCC_READ 0x1c00690 1 0>,
				<DCC_READ 0x1c00694 1 0>,
				<DCC_READ 0x1c00698 1 0>,
				<DCC_READ 0x1c0069c 1 0>,
				<DCC_READ 0x1c006a0 1 0>,
				<DCC_READ 0x1c006a4 1 0>,
				<DCC_READ 0x1c006a8 1 0>,
				<DCC_READ 0x1c006ac 1 0>,
				<DCC_READ 0x1c006b0 1 0>,
				<DCC_READ 0x1c006b4 1 0>,
				<DCC_READ 0x1c006b8 1 0>,
				<DCC_READ 0x1c01000 1 0>,
				<DCC_READ 0x1c01004 1 0>,
				<DCC_READ 0x1c01008 1 0>,
				<DCC_READ 0x1c0100C 1 0>,
				<DCC_READ 0x1c01010 1 0>,
				<DCC_READ 0x1c01014 1 0>,
				<DCC_READ 0x1c01018 1 0>,
				<DCC_READ 0x1c02000 1 0>,
				<DCC_READ 0x1c02800 1 0>,
				<DCC_READ 0x1c02804 1 0>,
				<DCC_READ 0x1c02c00 1 0>,
				<DCC_READ 0x1c02c04 1 0>,
				<DCC_READ 0x1c02c08 1 0>,
				<DCC_READ 0x1c02c0c 1 0>,
				<DCC_READ 0x1c02c10 1 0>,
				<DCC_READ 0x1c02c14 1 0>,
				<DCC_READ 0x1c02c18 1 0>,
				<DCC_READ 0x1c02c1C 1 0>,
				<DCC_READ 0x1c02c40 1 0>,
				<DCC_READ 0x1c02c44 1 0>,
				<DCC_READ 0x1c02c48 1 0>,
				<DCC_READ 0x1c02c68 1 0>,
				<DCC_READ 0x1c02c6C 1 0>,
				<DCC_READ 0x1c02c70 1 0>,
				<DCC_READ 0x1c02c80 1 0>,
				<DCC_READ 0x1c02c84 1 0>,
				<DCC_READ 0x1c02c88 1 0>,
				<DCC_READ 0x1c02c8C 1 0>,
				<DCC_READ 0x1c02c90 1 0>,
				<DCC_READ 0x1c02c94 1 0>,
				<DCC_READ 0x1c02c98 1 0>,
				<DCC_READ 0x1D0137C 1 0>,
				<DCC_READ 0x1D01000 1 0>,
				<DCC_READ 0x1D01004 1 0>,
				<DCC_READ 0x1D0384C 1 0>,
				<DCC_READ 0x1D01370 1 0>,
				<DCC_READ 0x1D03824 1 0>,
				<DCC_READ 0x1D03804 1 0>,
				<DCC_READ 0x1D03808 1 0>,
				<DCC_READ 0x1D0340C 1 0>,
				<DCC_READ 0x1D03420 1 0>,
				<DCC_READ 0x1D03434 1 0>,
				<DCC_READ 0x1D03448 1 0>,
				<DCC_READ 0x1D0345c 1 0>,
				<DCC_READ 0x1D03470 1 0>,
				<DCC_READ 0x1D03544 1 0>,
				<DCC_READ 0x1D05814 1 0>,
				<DCC_READ 0x1D05854 1 0>,
				<DCC_READ 0x1D05894 1 0>,
				<DCC_READ 0x1D058D4 1 0>,
				<DCC_READ 0x1D05914 1 0>,
				<DCC_READ 0x1D0583C 1 0>,
				<DCC_READ 0x1D0587C 1 0>,
				<DCC_READ 0x1D058BC 1 0>,
				<DCC_READ 0x1D058FC 1 0>,
				<DCC_READ 0x1D0593C 1 0>,
				<DCC_READ 0x1D0597C 1 0>,
				<DCC_READ 0x1C02C20 1 0>,
				<DCC_READ 0x1C02C24 1 0>,
				<DCC_READ 0x1C02C28 1 0>,
				<DCC_READ 0x1C02C2C 1 0>,
				<DCC_READ 0x1C02C30 1 0>,
				<DCC_READ 0x1C02C34 1 0>,
				<DCC_READ 0x1C02C38 1 0>,
				<DCC_READ 0x1C02C3C 1 0>;
		};
	};

	mem_dump {
		compatible = "qcom,mem-dump";
		memory-region = <&dump_mem>;

		static_dump {
			qcom,static-mem-dump;

			c0_context {
				qcom,dump-size = <0x800>;
				qcom,dump-id = <0x0>;
			};

			c100_context {
				qcom,dump-size = <0x800>;
				qcom,dump-id = <0x1>;
			};

			c200_context {
				qcom,dump-size = <0x800>;
				qcom,dump-id = <0x2>;
			};

			c300_context {
				qcom,dump-size = <0x800>;
				qcom,dump-id = <0x3>;
			};

			c400_context {
				qcom,dump-size = <0x800>;
				qcom,dump-id = <0x4>;
			};

			c500_context {
				qcom,dump-size = <0x800>;
				qcom,dump-id = <0x5>;
			};

			c600_context {
				qcom,dump-size = <0x800>;
				qcom,dump-id = <0x6>;
			};

			c700_context {
				qcom,dump-size = <0x800>;
				qcom,dump-id = <0x7>;
			};

			rpmh {
				qcom,dump-size = <0x400000>;
				qcom,dump-id = <0xec>;
			};

			rpm_sw {
				qcom,dump-size = <0x28000>;
				qcom,dump-id = <0xea>;
			};

			pmic {
				qcom,dump-size = <0x200000>;
				qcom,dump-id = <0xe4>;
			};

			fcm {
				qcom,dump-size = <0x8400>;
				qcom,dump-id = <0xee>;
			};

			misc_data {
				qcom,dump-size = <0x1000>;
				qcom,dump-id = <0xe8>;
			};

			etf_swao {
				qcom,dump-size = <0x10000>;
				qcom,dump-id = <0xf1>;
			};

			etr_reg {
				qcom,dump-size = <0x1000>;
				qcom,dump-id = <0x100>;
			};

			etfswao_reg {
				qcom,dump-size = <0x1000>;
				qcom,dump-id = <0x102>;
			};

			etr1_reg {
				qcom,dump-size = <0x1000>;
				qcom,dump-id = <0x105>;
			};

			etf_slpi {
				qcom,dump-size = <0x4000>;
				qcom,dump-id = <0xf3>;
			};

			etfslpi_reg {
				qcom,dump-size = <0x1000>;
				qcom,dump-id = <0x103>;
			};

			etf_lpass {
				qcom,dump-size = <0x4000>;
				qcom,dump-id = <0xf4>;
			};

			etflpass_reg {
				qcom,dump-size = <0x1000>;
				qcom,dump-id = <0x104>;
			};

			osm_reg {
				qcom,dump-size = <0x400>;
				qcom,dump-id = <0x163>;
			};

			pcu_reg {
				qcom,dump-size = <0x400>;
				qcom,dump-id = <0x164>;
			};

			fsm_data {
				qcom,dump-size = <0x400>;
				qcom,dump-id = <0x165>;
			};

			scandump_smmu {
				qcom,dump-size = <0x40000>;
				qcom,dump-id = <0x220>;
			};

			apps_scandump {
				qcom,dump-size = <0x380000>;
				qcom,dump-id = <0x130>;
			};
		};

		dynamic_mem_dump {
			qcom,dynamic-mem-dump;

			scandump_gpu {
				scandump_gpu {
					qcom,dump-size = <0x300000>;
					qcom,dump-id = <0x221>;
				};
			};

			cpuss_reg {
				cpuss_reg {
					qcom,dump-size = <0xa00000>;
					qcom,dump-id = <0xef>;
				};
			};

			spr {
				spr_cpu0 {
					qcom,dump-size = <0x2000>;
					qcom,dump-id = <0x1f0>;
				};

				spr_cpu1 {
					qcom,dump-size = <0x2000>;
					qcom,dump-id = <0x1f1>;
				};

				spr_cpu2 {
					qcom,dump-size = <0x2000>;
					qcom,dump-id = <0x1f2>;
				};

				spr_cpu3 {
					qcom,dump-size = <0x2000>;
					qcom,dump-id = <0x1f3>;
				};

				spr_cpu4 {
					qcom,dump-size = <0x2000>;
					qcom,dump-id = <0x1f4>;
				};

				spr_cpu5 {
					qcom,dump-size = <0x2000>;
					qcom,dump-id = <0x1f5>;
				};

				spr_cpu6 {
					qcom,dump-size = <0x2000>;
					qcom,dump-id = <0x1f6>;
				};

				spr_cpu7 {
					qcom,dump-size = <0x2000>;
					qcom,dump-id = <0x1f7>;
				};
			};

			cpuss_cpu {
				cpuss_cpu0 {
					qcom,dump-size = <0x40000>;
					qcom,dump-id = <0x280>;
				};

				cpuss_cpu1 {
					qcom,dump-size = <0x40000>;
					qcom,dump-id = <0x281>;
				};

				cpuss_cpu2 {
					qcom,dump-size = <0x40000>;
					qcom,dump-id = <0x282>;
				};

				cpuss_cpu3 {
					qcom,dump-size = <0x40000>;
					qcom,dump-id = <0x283>;
				};

				cpuss_cpu4 {
					qcom,dump-size = <0x40000>;
					qcom,dump-id = <0x284>;
				};

				cpuss_cpu5 {
					qcom,dump-size = <0x40000>;
					qcom,dump-id = <0x285>;
				};

				cpuss_cpu6 {
					qcom,dump-size = <0x40000>;
					qcom,dump-id = <0x286>;
				};

				cpuss_cpu7 {
					qcom,dump-size = <0x40000>;
					qcom,dump-id = <0x287>;
				};
			};

			cpuss_cluster {
				cpuss_cluster0 {
					qcom,dump-size = <0x40000>;
					qcom,dump-id = <0x270>;
				};

				cpuss_cluster1 {
					qcom,dump-size = <0x40000>;
					qcom,dump-id = <0x271>;
				};
			};

			cpucp {
				cpucp {
					qcom,dump-size = <0x80000>;
					qcom,dump-id = <0xf5>;
				};
			};

			cpu_cache {
				cache_cpu0 {
					qcom,dump-size = <0x2aa000>;
					qcom,dump-id = <0x230>;
				};

				cache_cpu1 {
					qcom,dump-size = <0x2aa000>;
					qcom,dump-id = <0x231>;
				};

				cache_cpu2 {
					qcom,dump-size = <0x2aa000>;
					qcom,dump-id = <0x232>;
				};

				cache_cpu3 {
					qcom,dump-size = <0x2aa000>;
					qcom,dump-id = <0x233>;
				};

				cache_cpu4 {
					qcom,dump-size = <0x2aa000>;
					qcom,dump-id = <0x234>;
				};

				cache_cpu5 {
					qcom,dump-size = <0x2aa000>;
					qcom,dump-id = <0x235>;
				};

				cache_cpu6 {
					qcom,dump-size = <0x2aa000>;
					qcom,dump-id = <0x236>;
				};

				cache_cpu7 {
					qcom,dump-size = <0x2aa000>;
					qcom,dump-id = <0x237>;
				};
			};

			cluster_cache {
				cl_cache0 {
					qcom,dump-size = <0x1400000>;
					qcom,dump-id = <0x240>;
				};

				cl_cache1 {
					qcom,dump-size = <0x1400000>;
					qcom,dump-id = <0x241>;
				};

			};
		};
	};
};
